AUTOSAR XML (schema 00048)
package /COM/VECTOR/CFG/WORKFLOW/SYSDESC/SYNC
  system SYSTEM: category=ECU_EXTRACT
    system mapping MAPPINGS
      data-mappings:
        sender-receiver-to-signal-mapping={communication-direction=OUT, data-element=COMPOSITIONTYPE.SP_IF_BMC_Abschaltankuendigung_XIX_BMC_HV.DE_BMC_Abschaltankuendigung, system-signal=BMC_Abschaltankuendigung}
        sender-receiver-to-signal-mapping={communication-direction=OUT, data-element=COMPOSITIONTYPE.SP_IF_BMC_Bidi_Energie_Absolut_XIX_BMC_HV.DE_BMC_Bidi_Energie_Absolut, system-signal=BMC_Bidi_Energie_Absolut}
        sender-receiver-to-signal-mapping={communication-direction=OUT, data-element=COMPOSITIONTYPE.SP_IF_BMC_Bidi_GenutzteEnergie_XIX_BMC_HV.DE_BMC_Bidi_GenutzteEnergie, system-signal=BMC_Bidi_GenutzteEnergie}
        sender-receiver-to-signal-mapping={communication-direction=OUT, data-element=COMPOSITIONTYPE.SP_IF_BMC_Bidi_Max_SoC_XIX_BMC_HV.DE_BMC_Bidi_Max_SoC, system-signal=BMC_Bidi_Max_SoC}
        sender-receiver-to-signal-mapping={communication-direction=OUT, data-element=COMPOSITIONTYPE.SP_IF_BMC_Bidi_Min_SoC_XIX_BMC_HV.DE_BMC_Bidi_Min_SoC, system-signal=BMC_Bidi_Min_SoC}
        sender-receiver-to-signal-mapping={communication-direction=OUT, data-element=COMPOSITIONTYPE.SP_IF_BMC_CMC_Temperatur_{001..019}_XIX_BMC_HV.DE_BMC_CMC_Temperatur_{001..019}, system-signal=BMC_CMC_Temperatur_{001..019}}
        sender-receiver-to-signal-mapping={communication-direction=OUT, data-element=COMPOSITIONTYPE.SP_IF_BMC_CMC_Temperatur_01_Messzeit_XIX_BMC_HV.DE_BMC_CMC_Temperatur_01_Messzeit, system-signal=BMC_CMC_Temperatur_01_Messzeit}
        sender-receiver-to-signal-mapping={communication-direction=OUT, data-element=COMPOSITIONTYPE.SP_IF_BMC_CMC_Temperatur_{020..029}_XIX_BMC_HV.DE_BMC_CMC_Temperatur_{020..029}, system-signal=BMC_CMC_Temperatur_{020..029}}
        sender-receiver-to-signal-mapping={communication-direction=OUT, data-element=COMPOSITIONTYPE.SP_IF_BMC_CMC_Temperatur_02_Messzeit_XIX_BMC_HV.DE_BMC_CMC_Temperatur_02_Messzeit, system-signal=BMC_CMC_Temperatur_02_Messzeit}
        sender-receiver-to-signal-mapping={communication-direction=OUT, data-element=COMPOSITIONTYPE.SP_IF_BMC_CMC_Temperatur_{030..039}_XIX_BMC_HV.DE_BMC_CMC_Temperatur_{030..039}, system-signal=BMC_CMC_Temperatur_{030..039}}
        sender-receiver-to-signal-mapping={communication-direction=OUT, data-element=COMPOSITIONTYPE.SP_IF_BMC_CMC_Temperatur_03_Messzeit_XIX_BMC_HV.DE_BMC_CMC_Temperatur_03_Messzeit, system-signal=BMC_CMC_Temperatur_03_Messzeit}
        sender-receiver-to-signal-mapping={communication-direction=OUT, data-element=COMPOSITIONTYPE.SP_IF_BMC_CMC_Temperatur_{040..096}_XIX_BMC_HV.DE_BMC_CMC_Temperatur_{040..096}, system-signal=BMC_CMC_Temperatur_{040..096}}
        sender-receiver-to-signal-mapping={communication-direction=OUT, data-element=COMPOSITIONTYPE.SP_IF_BMC_CMC_Zellspannung_{001..019}_XIX_BMC_HV.DE_BMC_CMC_Zellspannung_{001..019}, system-signal=BMC_CMC_Zellspannung_{001..019}}
        sender-receiver-to-signal-mapping={communication-direction=OUT, data-element=COMPOSITIONTYPE.SP_IF_BMC_CMC_Zellspannung_01_Messzeit_XIX_BMC_HV.DE_BMC_CMC_Zellspannung_01_Messzeit, system-signal=BMC_CMC_Zellspannung_01_Messzeit}
        sender-receiver-to-signal-mapping={communication-direction=OUT, data-element=COMPOSITIONTYPE.SP_IF_BMC_CMC_Zellspannung_{020..029}_XIX_BMC_HV.DE_BMC_CMC_Zellspannung_{020..029}, system-signal=BMC_CMC_Zellspannung_{020..029}}
        sender-receiver-to-signal-mapping={communication-direction=OUT, data-element=COMPOSITIONTYPE.SP_IF_BMC_CMC_Zellspannung_02_Messzeit_XIX_BMC_HV.DE_BMC_CMC_Zellspannung_02_Messzeit, system-signal=BMC_CMC_Zellspannung_02_Messzeit}
        sender-receiver-to-signal-mapping={communication-direction=OUT, data-element=COMPOSITIONTYPE.SP_IF_BMC_CMC_Zellspannung_{030..039}_XIX_BMC_HV.DE_BMC_CMC_Zellspannung_{030..039}, system-signal=BMC_CMC_Zellspannung_{030..039}}
        sender-receiver-to-signal-mapping={communication-direction=OUT, data-element=COMPOSITIONTYPE.SP_IF_BMC_CMC_Zellspannung_03_Messzeit_XIX_BMC_HV.DE_BMC_CMC_Zellspannung_03_Messzeit, system-signal=BMC_CMC_Zellspannung_03_Messzeit}
        sender-receiver-to-signal-mapping={communication-direction=OUT, data-element=COMPOSITIONTYPE.SP_IF_BMC_CMC_Zellspannung_{040..049}_XIX_BMC_HV.DE_BMC_CMC_Zellspannung_{040..049}, system-signal=BMC_CMC_Zellspannung_{040..049}}
        sender-receiver-to-signal-mapping={communication-direction=OUT, data-element=COMPOSITIONTYPE.SP_IF_BMC_CMC_Zellspannung_04_Messzeit_XIX_BMC_HV.DE_BMC_CMC_Zellspannung_04_Messzeit, system-signal=BMC_CMC_Zellspannung_04_Messzeit}
        sender-receiver-to-signal-mapping={communication-direction=OUT, data-element=COMPOSITIONTYPE.SP_IF_BMC_CMC_Zellspannung_{050..059}_XIX_BMC_HV.DE_BMC_CMC_Zellspannung_{050..059}, system-signal=BMC_CMC_Zellspannung_{050..059}}
        sender-receiver-to-signal-mapping={communication-direction=OUT, data-element=COMPOSITIONTYPE.SP_IF_BMC_CMC_Zellspannung_05_Messzeit_XIX_BMC_HV.DE_BMC_CMC_Zellspannung_05_Messzeit, system-signal=BMC_CMC_Zellspannung_05_Messzeit}
        sender-receiver-to-signal-mapping={communication-direction=OUT, data-element=COMPOSITIONTYPE.SP_IF_BMC_CMC_Zellspannung_{060..192}_XIX_BMC_HV.DE_BMC_CMC_Zellspannung_{060..192}, system-signal=BMC_CMC_Zellspannung_{060..192}}
        sender-receiver-to-signal-mapping={communication-direction=OUT, data-element=COMPOSITIONTYPE.SP_IF_BMC_Dauer_Entladeleistung_02_XIX_BMC_HV.DE_BMC_Dauer_Entladeleistung_02, system-signal=BMC_Dauer_Entladeleistung_02}
        sender-receiver-to-signal-mapping={communication-direction=OUT, data-element=COMPOSITIONTYPE.SP_IF_BMC_Dauer_Entladeleistung_XIX_BMC_HV.DE_BMC_Dauer_Entladeleistung, system-signal=BMC_Dauer_Entladeleistung}
        sender-receiver-to-signal-mapping={communication-direction=OUT, data-element=COMPOSITIONTYPE.SP_IF_BMC_Dauer_Ladeleistung_02_XIX_BMC_HV.DE_BMC_Dauer_Ladeleistung_02, system-signal=BMC_Dauer_Ladeleistung_02}
        sender-receiver-to-signal-mapping={communication-direction=OUT, data-element=COMPOSITIONTYPE.SP_IF_BMC_Dauer_Ladeleistung_XIX_BMC_HV.DE_BMC_Dauer_Ladeleistung, system-signal=BMC_Dauer_Ladeleistung}
        sender-receiver-to-signal-mapping={communication-direction=OUT, data-element=COMPOSITIONTYPE.SP_IF_BMC_Energie_Entladen_XIX_BMC_HV.DE_BMC_Energie_Entladen, system-signal=BMC_Energie_Entladen}
        sender-receiver-to-signal-mapping={communication-direction=OUT, data-element=COMPOSITIONTYPE.SP_IF_BMC_Energie_Laden_XIX_BMC_HV.DE_BMC_Energie_Laden, system-signal=BMC_Energie_Laden}
        sender-receiver-to-signal-mapping={communication-direction=OUT, data-element=COMPOSITIONTYPE.SP_IF_BMC_EnergieVorhalt_XIX_BMC_HV.DE_BMC_EnergieVorhalt, system-signal=BMC_EnergieVorhalt}
        sender-receiver-to-signal-mapping={communication-direction=OUT, data-element=COMPOSITIONTYPE.SP_IF_BMC_ExtLadeleistung_XIX_BMC_HV.DE_BMC_ExtLadeleistung, system-signal=BMC_ExtLadeleistung}
        sender-receiver-to-signal-mapping={communication-direction=OUT, data-element=COMPOSITIONTYPE.SP_IF_BMC_IstTemperaturMax_Modul_ID_XIX_BMC_HV.DE_BMC_IstTemperaturMax_Modul_ID, system-signal=BMC_IstTemperaturMax_Modul_ID}
        sender-receiver-to-signal-mapping={communication-direction=OUT, data-element=COMPOSITIONTYPE.SP_IF_BMC_IstTemperaturMax_Sensor_ID_XIX_BMC_HV.DE_BMC_IstTemperaturMax_Sensor_ID, system-signal=BMC_IstTemperaturMax_Sensor_ID}
        sender-receiver-to-signal-mapping={communication-direction=OUT, data-element=COMPOSITIONTYPE.SP_IF_BMC_IstTemperaturMin_Modul_ID_XIX_BMC_HV.DE_BMC_IstTemperaturMin_Modul_ID, system-signal=BMC_IstTemperaturMin_Modul_ID}
        sender-receiver-to-signal-mapping={communication-direction=OUT, data-element=COMPOSITIONTYPE.SP_IF_BMC_IstTemperaturMin_Sensor_ID_XIX_BMC_HV.DE_BMC_IstTemperaturMin_Sensor_ID, system-signal=BMC_IstTemperaturMin_Sensor_ID}
        sender-receiver-to-signal-mapping={communication-direction=OUT, data-element=COMPOSITIONTYPE.SP_IF_BMC_IstZellSpannungMax_Modul_ID_XIX_BMC_HV.DE_BMC_IstZellSpannungMax_Modul_ID, system-signal=BMC_IstZellSpannungMax_Modul_ID}
        sender-receiver-to-signal-mapping={communication-direction=OUT, data-element=COMPOSITIONTYPE.SP_IF_BMC_IstZellSpannungMax_Zell_ID_XIX_BMC_HV.DE_BMC_IstZellSpannungMax_Zell_ID, system-signal=BMC_IstZellSpannungMax_Zell_ID}
        sender-receiver-to-signal-mapping={communication-direction=OUT, data-element=COMPOSITIONTYPE.SP_IF_BMC_IstZellSpannungMin_Modul_ID_XIX_BMC_HV.DE_BMC_IstZellSpannungMin_Modul_ID, system-signal=BMC_IstZellSpannungMin_Modul_ID}
        sender-receiver-to-signal-mapping={communication-direction=OUT, data-element=COMPOSITIONTYPE.SP_IF_BMC_IstZellSpannungMin_Zell_ID_XIX_BMC_HV.DE_BMC_IstZellSpannungMin_Zell_ID, system-signal=BMC_IstZellSpannungMin_Zell_ID}
        sender-receiver-to-signal-mapping={communication-direction=OUT, data-element=COMPOSITIONTYPE.SP_IF_BMC_Max_Entladeleistung_02_XIX_BMC_HV.DE_BMC_Max_Entladeleistung_02, system-signal=BMC_Max_Entladeleistung_02}
        sender-receiver-to-signal-mapping={communication-direction=OUT, data-element=COMPOSITIONTYPE.SP_IF_BMC_Max_Entladestrom_02_XIX_BMC_HV.DE_BMC_Max_Entladestrom_02, system-signal=BMC_Max_Entladestrom_02}
        sender-receiver-to-signal-mapping={communication-direction=OUT, data-element=COMPOSITIONTYPE.SP_IF_BMC_Max_Ladeleistung_02_XIX_BMC_HV.DE_BMC_Max_Ladeleistung_02, system-signal=BMC_Max_Ladeleistung_02}
        sender-receiver-to-signal-mapping={communication-direction=OUT, data-element=COMPOSITIONTYPE.SP_IF_BMC_Max_Ladestrom_02_XIX_BMC_HV.DE_BMC_Max_Ladestrom_02, system-signal=BMC_Max_Ladestrom_02}
        sender-receiver-to-signal-mapping={communication-direction=OUT, data-element=COMPOSITIONTYPE.SP_IF_BMC_Max_Spannung_XIX_BMC_HV.DE_BMC_Max_Spannung, system-signal=BMC_Max_Spannung}
        sender-receiver-to-signal-mapping={communication-direction=OUT, data-element=COMPOSITIONTYPE.SP_IF_BMC_MaxEnergieinhalt_XIX_BMC_HV.DE_BMC_MaxEnergieinhalt, system-signal=BMC_MaxEnergieinhalt}
        sender-receiver-to-signal-mapping={communication-direction=OUT, data-element=COMPOSITIONTYPE.SP_IF_BMC_Min_Spannung_XIX_BMC_HV.DE_BMC_Min_Spannung, system-signal=BMC_Min_Spannung}
        sender-receiver-to-signal-mapping={communication-direction=OUT, data-element=COMPOSITIONTYPE.SP_IF_BMC_NutzbareKapazitaet_XIX_BMC_HV.DE_BMC_NutzbareKapazitaet, system-signal=BMC_NutzbareKapazitaet}
        sender-receiver-to-signal-mapping={communication-direction=OUT, data-element=COMPOSITIONTYPE.SP_IF_BMC_Range_Indikator_XIX_BMC_HV.DE_BMC_Range_Indikator, system-signal=BMC_Range_Indikator}
        sender-receiver-to-signal-mapping={communication-direction=OUT, data-element=COMPOSITIONTYPE.SP_IF_BMC_Rekuperation_XIX_BMC_HV.DE_BMC_Rekuperation, system-signal=BMC_Rekuperation}
        sender-receiver-to-signal-mapping={communication-direction=OUT, data-element=COMPOSITIONTYPE.SP_IF_BMC_RuecklaufTemperatur_XIX_BMC_HV.DE_BMC_RuecklaufTemperatur, system-signal=BMC_RuecklaufTemperatur}
        sender-receiver-to-signal-mapping={communication-direction=OUT, data-element=COMPOSITIONTYPE.SP_IF_BMC_Temperatur_hoechste_XIX_BMC_HV.DE_BMC_Temperatur_hoechste, system-signal=BMC_Temperatur_hoechste}
        sender-receiver-to-signal-mapping={communication-direction=OUT, data-element=COMPOSITIONTYPE.SP_IF_BMC_Temperatur_niedrigste_XIX_BMC_HV.DE_BMC_Temperatur_niedrigste, system-signal=BMC_Temperatur_niedrigste}
        sender-receiver-to-signal-mapping={communication-direction=OUT, data-element=COMPOSITIONTYPE.SP_IF_BMC_Temperatur_XIX_BMC_HV.DE_BMC_Temperatur, system-signal=BMC_Temperatur}
        sender-receiver-to-signal-mapping={communication-direction=OUT, data-element=COMPOSITIONTYPE.SP_IF_BMC_ThermAuslastung_XIX_BMC_HV.DE_BMC_ThermAuslastung, system-signal=BMC_ThermAuslastung}
        sender-receiver-to-signal-mapping={communication-direction=OUT, data-element=COMPOSITIONTYPE.SP_IF_BMC_ThermSpreizung_XIX_BMC_HV.DE_BMC_ThermSpreizung, system-signal=BMC_ThermSpreizung}
        sender-receiver-to-signal-mapping={communication-direction=OUT, data-element=COMPOSITIONTYPE.SP_IF_BMC_UBE_Indik_last_update_km_XIX_BMC_HV.DE_BMC_UBE_Indik_last_update_km, system-signal=BMC_UBE_Indik_last_update_km}
        sender-receiver-to-signal-mapping={communication-direction=OUT, data-element=COMPOSITIONTYPE.SP_IF_BMC_UBE_Indikator_XIX_BMC_HV.DE_BMC_UBE_Indikator, system-signal=BMC_UBE_Indikator}
        sender-receiver-to-signal-mapping={communication-direction=OUT, data-element=COMPOSITIONTYPE.SP_IF_BMC_Verbrauch_XIX_BMC_HV.DE_BMC_Verbrauch, system-signal=BMC_Verbrauch}
        sender-receiver-to-signal-mapping={communication-direction=OUT, data-element=COMPOSITIONTYPE.SP_IF_BMC_VerlustEnergie_XIX_BMC_HV.DE_BMC_VerlustEnergie, system-signal=BMC_VerlustEnergie}
        sender-receiver-to-signal-mapping={communication-direction=OUT, data-element=COMPOSITIONTYPE.SP_IF_BMC_VorlaufTemperatur_XIX_BMC_HV.DE_BMC_VorlaufTemperatur, system-signal=BMC_VorlaufTemperatur}
        sender-receiver-to-signal-mapping={communication-direction=OUT, data-element=COMPOSITIONTYPE.SP_IF_DS_Hybrid_01_ConfDTCChanged_XIX_BMC_HV.DE_DS_Hybrid_01_ConfDTCChanged, system-signal=DS_Hybrid_01_ConfDTCChanged}
        sender-receiver-to-signal-mapping={communication-direction=OUT, data-element=COMPOSITIONTYPE.SP_IF_DS_Hybrid_01_DiagAdr_XIX_BMC_HV.DE_DS_Hybrid_01_DiagAdr, system-signal=DS_Hybrid_01_DiagAdr}
        sender-receiver-to-signal-mapping={communication-direction=OUT, data-element=COMPOSITIONTYPE.SP_IF_DS_Hybrid_01_MemSel10Changed_XIX_BMC_HV.DE_DS_Hybrid_01_MemSel10Changed, system-signal=DS_Hybrid_01_MemSel10Changed}
        sender-receiver-to-signal-mapping={communication-direction=OUT, data-element=COMPOSITIONTYPE.SP_IF_DS_Hybrid_01_MemSelChanged_XIX_BMC_HV.DE_DS_Hybrid_01_MemSelChanged, system-signal=DS_Hybrid_01_MemSelChanged}
        sender-receiver-to-signal-mapping={communication-direction=OUT, data-element=COMPOSITIONTYPE.SP_IF_DS_Hybrid_01_StMemChanged_XIX_BMC_HV.DE_DS_Hybrid_01_StMemChanged, system-signal=DS_Hybrid_01_StMemChanged}
        sender-receiver-to-signal-mapping={communication-direction=OUT, data-element=COMPOSITIONTYPE.SP_IF_DS_Hybrid_01_TestFailedChanged_XIX_BMC_HV.DE_DS_Hybrid_01_TestFailedChanged, system-signal=DS_Hybrid_01_TestFailedChanged}
        sender-receiver-to-signal-mapping={communication-direction=OUT, data-element=COMPOSITIONTYPE.SP_IF_DS_Hybrid_01_WIRChanged_XIX_BMC_HV.DE_DS_Hybrid_01_WIRChanged, system-signal=DS_Hybrid_01_WIRChanged}
        sender-receiver-to-signal-mapping={communication-direction=OUT, data-element=COMPOSITIONTYPE.SP_IF_Hybrid_01_SNI_10_XIX_BMC_HV.DE_Hybrid_01_SNI_10, system-signal=Hybrid_01_SNI_10}
        sender-receiver-to-signal-mapping={communication-direction=OUT, data-element=COMPOSITIONTYPE.SP_IF_SOK_Zeit_Hybrid_01_Challenge_XIX_BMC_HV.DE_SOK_Zeit_Hybrid_01_Challenge, system-signal=SOK_Zeit_Hybrid_01_Challenge}
        sender-receiver-to-signal-mapping={communication-direction=IN, data-element=COMPOSITIONTYPE.RP_IF_BJB_CALID_Index_{01..16}_XIX_BMC_HV.DE_BJB_CALID_Index_{01..16}, system-signal=BJB_CALID_Index_{01..16}}
        sender-receiver-to-signal-mapping={communication-direction=IN, data-element=COMPOSITIONTYPE.RP_IF_BJB_CVN_Byte_{1..4}_XIX_BMC_HV.DE_BJB_CVN_Byte_{1..4}, system-signal=BJB_CVN_Byte_{1..4}}
        sender-receiver-to-signal-mapping={communication-direction=IN, data-element=COMPOSITIONTYPE.RP_IF_BJB_CVN_VLD_XIX_BMC_HV.DE_BJB_CVN_VLD, system-signal=BJB_CVN_VLD}
        sender-receiver-to-signal-mapping={communication-direction=IN, data-element=COMPOSITIONTYPE.RP_IF_CHA_ReqPrgBms_XIX_BMC_HV.DE_CHA_ReqPrgBms, system-signal=CHA_ReqPrgBms}
        sender-receiver-to-signal-mapping={communication-direction=IN, data-element=COMPOSITIONTYPE.RP_IF_DC_IstLeistung_HV_XIX_BMC_HV.DE_DC_IstLeistung_HV, system-signal=DC_IstLeistung_HV}
        sender-receiver-to-signal-mapping={communication-direction=IN, data-element=COMPOSITIONTYPE.RP_IF_DCDC_NV_CALID_Index_{01..16}_XIX_BMC_HV.DE_DCDC_NV_CALID_Index_{01..16}, system-signal=DCDC_NV_CALID_Index_{01..16}}
        sender-receiver-to-signal-mapping={communication-direction=IN, data-element=COMPOSITIONTYPE.RP_IF_DCDC_NV_CVN_Byte_{1..4}_XIX_BMC_HV.DE_DCDC_NV_CVN_Byte_{1..4}, system-signal=DCDC_NV_CVN_Byte_{1..4}}
        sender-receiver-to-signal-mapping={communication-direction=IN, data-element=COMPOSITIONTYPE.RP_IF_DCDC_NV_CVN_VLD_XIX_BMC_HV.DE_DCDC_NV_CVN_VLD, system-signal=DCDC_NV_CVN_VLD}
        sender-receiver-to-signal-mapping={communication-direction=IN, data-element=COMPOSITIONTYPE.RP_IF_DCDC_NV_Komponentenfehler_{01..39}_XIX_BMC_HV.DE_DCDC_NV_Komponentenfehler_{01..39}, system-signal=DCDC_NV_Komponentenfehler_{01..39}}
        sender-receiver-to-signal-mapping={communication-direction=IN, data-element=COMPOSITIONTYPE.RP_IF_DCDC_NV_Komponentenfehler_3_{10..16}_XIX_BMC_HV.DE_DCDC_NV_Komponentenfehler_3_{10..16}, system-signal=DCDC_NV_Komponentenfehler_3_{10..16}}
        sender-receiver-to-signal-mapping={communication-direction=IN, data-element=COMPOSITIONTYPE.RP_IF_DCDC_NV_Komponentenfehler_3_{1..9}_XIX_BMC_HV.DE_DCDC_NV_Komponentenfehler_3_{1..9}, system-signal=DCDC_NV_Komponentenfehler_3_{1..9}}
        sender-receiver-to-signal-mapping={communication-direction=IN, data-element=COMPOSITIONTYPE.RP_IF_DCDC_NV_Komponentenfehler_{40..80}_XIX_BMC_HV.DE_DCDC_NV_Komponentenfehler_{40..80}, system-signal=DCDC_NV_Komponentenfehler_{40..80}}
        sender-receiver-to-signal-mapping={communication-direction=IN, data-element=COMPOSITIONTYPE.RP_IF_DCDC_NV_Komponentenfehler_VLD_XIX_BMC_HV.DE_DCDC_NV_Komponentenfehler_VLD, system-signal=DCDC_NV_Komponentenfehler_VLD}
        sender-receiver-to-signal-mapping={communication-direction=IN, data-element=COMPOSITIONTYPE.RP_IF_DW_Kilometerstand_XIX_BMC_HV.DE_DW_Kilometerstand, system-signal=DW_Kilometerstand}
        sender-receiver-to-signal-mapping={communication-direction=IN, data-element=COMPOSITIONTYPE.RP_IF_EKK_HVK_EoHVL_Status_XIX_BMC_HV.DE_EKK_HVK_EoHVL_Status, system-signal=EKK_HVK_EoHVL_Status}
        sender-receiver-to-signal-mapping={communication-direction=IN, data-element=COMPOSITIONTYPE.RP_IF_HVEM_BMC_CHA_Wunschleistung_02_XIX_BMC_HV.DE_HVEM_BMC_CHA_Wunschleistung_02, system-signal=HVEM_BMC_CHA_Wunschleistung_02}
        sender-receiver-to-signal-mapping={communication-direction=IN, data-element=COMPOSITIONTYPE.RP_IF_HVEM_BMC_CHA_Wunschleistung_XIX_BMC_HV.DE_HVEM_BMC_CHA_Wunschleistung, system-signal=HVEM_BMC_CHA_Wunschleistung}
        sender-receiver-to-signal-mapping={communication-direction=IN, data-element=COMPOSITIONTYPE.RP_IF_HVEM_MMTR_State_XIX_BMC_HV.DE_HVEM_MMTR_State, system-signal=HVEM_MMTR_State}
        sender-receiver-to-signal-mapping={communication-direction=IN, data-element=COMPOSITIONTYPE.RP_IF_HVEM_SystemMinLeistungsgrenze_XIX_BMC_HV.DE_HVEM_SystemMinLeistungsgrenze, system-signal=HVEM_SystemMinLeistungsgrenze}
        sender-receiver-to-signal-mapping={communication-direction=IN, data-element=COMPOSITIONTYPE.RP_IF_HVLE_IstSpannung_HV_XIX_BMC_HV.DE_HVLE_IstSpannung_HV, system-signal=HVLE_IstSpannung_HV}
        sender-receiver-to-signal-mapping={communication-direction=IN, data-element=COMPOSITIONTYPE.RP_IF_HVLE_OBG_IstModus_XIX_BMC_HV.DE_HVLE_OBG_IstModus, system-signal=HVLE_OBG_IstModus}
        sender-receiver-to-signal-mapping={communication-direction=IN, data-element=COMPOSITIONTYPE.RP_IF_HVLM_BCAM_Aktiv_XIX_BMC_HV.DE_HVLM_BCAM_Aktiv, system-signal=HVLM_BCAM_Aktiv}
        sender-receiver-to-signal-mapping={communication-direction=IN, data-element=COMPOSITIONTYPE.RP_IF_HVLM_BidiLadeModus_XIX_BMC_HV.DE_HVLM_BidiLadeModus, system-signal=HVLM_BidiLadeModus}
        sender-receiver-to-signal-mapping={communication-direction=IN, data-element=COMPOSITIONTYPE.RP_IF_KST_KL_15_XIX_BMC_HV.DE_KST_KL_15, system-signal=KST_KL_15}
        sender-receiver-to-signal-mapping={communication-direction=IN, data-element=COMPOSITIONTYPE.RP_IF_MM_PropulsionSystemActive_XIX_BMC_HV.DE_MM_PropulsionSystemActive, system-signal=MM_PropulsionSystemActive}
        sender-receiver-to-signal-mapping={communication-direction=IN, data-element=COMPOSITIONTYPE.RP_IF_NVEM_Abschaltstufe_XIX_BMC_HV.DE_NVEM_Abschaltstufe, system-signal=NVEM_Abschaltstufe}
        sender-receiver-to-signal-mapping={communication-direction=IN, data-element=COMPOSITIONTYPE.RP_IF_OBD_Abs_Pedal_Pos_XIX_BMC_HV.DE_OBD_Abs_Pedal_Pos, system-signal=OBD_Abs_Pedal_Pos}
        sender-receiver-to-signal-mapping={communication-direction=IN, data-element=COMPOSITIONTYPE.RP_IF_OBD_Aussen_Temp_gef_XIX_BMC_HV.DE_OBD_Aussen_Temp_gef, system-signal=OBD_Aussen_Temp_gef}
        sender-receiver-to-signal-mapping={communication-direction=IN, data-element=COMPOSITIONTYPE.RP_IF_OBD_Barometric_Pressure_XIX_BMC_HV.DE_OBD_Barometric_Pressure, system-signal=OBD_Barometric_Pressure}
        sender-receiver-to-signal-mapping={communication-direction=IN, data-element=COMPOSITIONTYPE.RP_IF_OBD_Calc_Load_Val_XIX_BMC_HV.DE_OBD_Calc_Load_Val, system-signal=OBD_Calc_Load_Val}
        sender-receiver-to-signal-mapping={communication-direction=IN, data-element=COMPOSITIONTYPE.RP_IF_OBD_ClearMem_Inhibit_XIX_BMC_HV.DE_OBD_ClearMem_Inhibit, system-signal=OBD_ClearMem_Inhibit}
        sender-receiver-to-signal-mapping={communication-direction=IN, data-element=COMPOSITIONTYPE.RP_IF_OBD_Driving_Cycle_XIX_BMC_HV.DE_OBD_Driving_Cycle, system-signal=OBD_Driving_Cycle}
        sender-receiver-to-signal-mapping={communication-direction=IN, data-element=COMPOSITIONTYPE.RP_IF_OBD_Eng_Cool_Temp_XIX_BMC_HV.DE_OBD_Eng_Cool_Temp, system-signal=OBD_Eng_Cool_Temp}
        sender-receiver-to-signal-mapping={communication-direction=IN, data-element=COMPOSITIONTYPE.RP_IF_OBD_Engine_RPM_XIX_BMC_HV.DE_OBD_Engine_RPM, system-signal=OBD_Engine_RPM}
        sender-receiver-to-signal-mapping={communication-direction=IN, data-element=COMPOSITIONTYPE.RP_IF_OBD_Kaltstart_Denominator_XIX_BMC_HV.DE_OBD_Kaltstart_Denominator, system-signal=OBD_Kaltstart_Denominator}
        sender-receiver-to-signal-mapping={communication-direction=IN, data-element=COMPOSITIONTYPE.RP_IF_OBD_Minimum_Trip_XIX_BMC_HV.DE_OBD_Minimum_Trip, system-signal=OBD_Minimum_Trip}
        sender-receiver-to-signal-mapping={communication-direction=IN, data-element=COMPOSITIONTYPE.RP_IF_OBD_Normed_Trip_XIX_BMC_HV.DE_OBD_Normed_Trip, system-signal=OBD_Normed_Trip}
        sender-receiver-to-signal-mapping={communication-direction=IN, data-element=COMPOSITIONTYPE.RP_IF_OBD_NumDcyMilOnReq_XIX_BMC_HV.DE_OBD_NumDcyMilOnReq, system-signal=OBD_NumDcyMilOnReq}
        sender-receiver-to-signal-mapping={communication-direction=IN, data-element=COMPOSITIONTYPE.RP_IF_OBD_QBit_Aussen_Temp_XIX_BMC_HV.DE_OBD_QBit_Aussen_Temp, system-signal=OBD_QBit_Aussen_Temp}
        sender-receiver-to-signal-mapping={communication-direction=IN, data-element=COMPOSITIONTYPE.RP_IF_OBD_Sperrung_IUMPR_XIX_BMC_HV.DE_OBD_Sperrung_IUMPR, system-signal=OBD_Sperrung_IUMPR}
        sender-receiver-to-signal-mapping={communication-direction=IN, data-element=COMPOSITIONTYPE.RP_IF_OBD_Sperrung_Kaltstart_Denom_XIX_BMC_HV.DE_OBD_Sperrung_Kaltstart_Denom, system-signal=OBD_Sperrung_Kaltstart_Denom}
        sender-receiver-to-signal-mapping={communication-direction=IN, data-element=COMPOSITIONTYPE.RP_IF_OBD_Typ_XIX_BMC_HV.DE_OBD_Typ, system-signal=OBD_Typ}
        sender-receiver-to-signal-mapping={communication-direction=IN, data-element=COMPOSITIONTYPE.RP_IF_OBD_Warm_Up_Cycle_XIX_BMC_HV.DE_OBD_Warm_Up_Cycle, system-signal=OBD_Warm_Up_Cycle}
        sender-receiver-to-signal-mapping={communication-direction=IN, data-element=COMPOSITIONTYPE.RP_IF_OBDProtocol_req_XIX_BMC_HV.DE_OBDProtocol_req, system-signal=OBDProtocol_req}
        sender-receiver-to-signal-mapping={communication-direction=IN, data-element=COMPOSITIONTYPE.RP_IF_ORU_Status_XIX_BMC_HV.DE_ORU_Status, system-signal=ORU_Status}
        sender-receiver-to-signal-mapping={communication-direction=IN, data-element=COMPOSITIONTYPE.RP_IF_OTP_Aussen_Temp_OBD_XIX_BMC_HV.DE_OTP_Aussen_Temp_OBD, system-signal=OTP_Aussen_Temp_OBD}
        sender-receiver-to-signal-mapping={communication-direction=IN, data-element=COMPOSITIONTYPE.RP_IF_OTP_Aussen_Temp_ungef_XIX_BMC_HV.DE_OTP_Aussen_Temp_ungef, system-signal=OTP_Aussen_Temp_ungef}
        sender-receiver-to-signal-mapping={communication-direction=IN, data-element=COMPOSITIONTYPE.RP_IF_PCM_BMC_VTD_Freeze_Req_XIX_BMC_HV.DE_PCM_BMC_VTD_Freeze_Req, system-signal=PCM_BMC_VTD_Freeze_Req}
        sender-receiver-to-signal-mapping={communication-direction=IN, data-element=COMPOSITIONTYPE.RP_IF_PCM_BMC_VTD_LifeTimeReset_Req_XIX_BMC_HV.DE_PCM_BMC_VTD_LifeTimeReset_Req, system-signal=PCM_BMC_VTD_LifeTimeReset_Req}
        sender-receiver-to-signal-mapping={communication-direction=IN, data-element=COMPOSITIONTYPE.RP_IF_PCM_BMC_VTD_LifeTimeReset_Resp_XIX_BMC_HV.DE_PCM_BMC_VTD_LifeTimeReset_Resp, system-signal=PCM_BMC_VTD_LifeTimeReset_Resp}
        sender-receiver-to-signal-mapping={communication-direction=IN, data-element=COMPOSITIONTYPE.RP_IF_PCM_BMC_VTD_RecentReset_Req_XIX_BMC_HV.DE_PCM_BMC_VTD_RecentReset_Req, system-signal=PCM_BMC_VTD_RecentReset_Req}
        sender-receiver-to-signal-group-mapping={communication-direction=IN, data-element=COMPOSITIONTYPE.RP_IF_SG_KS_Hybrid_01_Challenge_M_XIX_BMC_HV.DE_SG_KS_Hybrid_01_Challenge_M, signal-group=SG_KS_Hybrid_01_Challenge_M, type-mapping=sender-rec-record-type-mapping=record-element-mappings=[{implementation-record-element=KS_Hybrid_01_ChM_SID, system-signal=KS_Hybrid_01_ChM_SID}, {implementation-record-element=KS_Hybrid_01_ChM_IKACtr, system-signal=KS_Hybrid_01_ChM_IKACtr}, {implementation-record-element=KS_Hybrid_01_ChM, system-signal=KS_Hybrid_01_ChM}]}
        sender-receiver-to-signal-group-mapping={communication-direction=IN, data-element=COMPOSITIONTYPE.RP_IF_SG_KS_Hybrid_01_Response_M_XIX_BMC_HV.DE_SG_KS_Hybrid_01_Response_M, signal-group=SG_KS_Hybrid_01_Response_M, type-mapping=sender-rec-record-type-mapping=record-element-mappings=[{implementation-record-element=KS_Hybrid_01_ReM_SID, system-signal=KS_Hybrid_01_ReM_SID}, {implementation-record-element=KS_Hybrid_01_ReM_IKACtr, system-signal=KS_Hybrid_01_ReM_IKACtr}, {implementation-record-element=KS_Hybrid_01_ReM, system-signal=KS_Hybrid_01_ReM}]}
        sender-receiver-to-signal-mapping={communication-direction=IN, data-element=COMPOSITIONTYPE.RP_IF_SI_NWDF_30_XIX_BMC_HV.DE_SI_NWDF_30, system-signal=SI_NWDF_30}
        sender-receiver-to-signal-mapping={communication-direction=IN, data-element=COMPOSITIONTYPE.RP_IF_SI_NWDF_XIX_BMC_HV.DE_SI_NWDF, system-signal=SI_NWDF}
        sender-receiver-to-signal-mapping={communication-direction=IN, data-element=COMPOSITIONTYPE.RP_IF_SI_P_Mode_gueltig_XIX_BMC_HV.DE_SI_P_Mode_gueltig, system-signal=SI_P_Mode_gueltig}
        sender-receiver-to-signal-mapping={communication-direction=IN, data-element=COMPOSITIONTYPE.RP_IF_SI_P_Mode_XIX_BMC_HV.DE_SI_P_Mode, system-signal=SI_P_Mode}
        sender-receiver-to-signal-mapping={communication-direction=IN, data-element=COMPOSITIONTYPE.RP_IF_SI_T_Mode_XIX_BMC_HV.DE_SI_T_Mode, system-signal=SI_T_Mode}
        sender-receiver-to-signal-mapping={communication-direction=IN, data-element=COMPOSITIONTYPE.RP_IF_SOK_ungeschuetzte_Zeit_XIX_BMC_HV.DE_SOK_ungeschuetzte_Zeit, system-signal=SOK_ungeschuetzte_Zeit}
        sender-receiver-to-signal-mapping={communication-direction=IN, data-element=COMPOSITIONTYPE.RP_IF_SOK_Zeit_Hybrid_01_Zeit_XIX_BMC_HV.DE_SOK_Zeit_Hybrid_01_Zeit, system-signal=SOK_Zeit_Hybrid_01_Zeit}
        sender-receiver-to-signal-mapping={communication-direction=IN, data-element=COMPOSITIONTYPE.RP_IF_TME_Batt_Kond_Verf_XIX_BMC_HV.DE_TME_Batt_Kond_Verf, system-signal=TME_Batt_Kond_Verf}
        sender-receiver-to-signal-mapping={communication-direction=IN, data-element=COMPOSITIONTYPE.RP_IF_TME_Therm_IstLeistung_HVBatterie_XIX_BMC_HV.DE_TME_Therm_IstLeistung_HVBatterie, system-signal=TME_Therm_IstLeistung_HVBatterie}
        sender-receiver-to-signal-mapping={communication-direction=IN, data-element=COMPOSITIONTYPE.RP_IF_UH_Jahr_XIX_BMC_HV.DE_UH_Jahr, system-signal=UH_Jahr}
        sender-receiver-to-signal-mapping={communication-direction=IN, data-element=COMPOSITIONTYPE.RP_IF_UH_Minute_XIX_BMC_HV.DE_UH_Minute, system-signal=UH_Minute}
        sender-receiver-to-signal-mapping={communication-direction=IN, data-element=COMPOSITIONTYPE.RP_IF_UH_Monat_XIX_BMC_HV.DE_UH_Monat, system-signal=UH_Monat}
        sender-receiver-to-signal-mapping={communication-direction=IN, data-element=COMPOSITIONTYPE.RP_IF_UH_Sekunde_XIX_BMC_HV.DE_UH_Sekunde, system-signal=UH_Sekunde}
        sender-receiver-to-signal-mapping={communication-direction=IN, data-element=COMPOSITIONTYPE.RP_IF_UH_Stunde_XIX_BMC_HV.DE_UH_Stunde, system-signal=UH_Stunde}
        sender-receiver-to-signal-mapping={communication-direction=IN, data-element=COMPOSITIONTYPE.RP_IF_UH_Tag_XIX_BMC_HV.DE_UH_Tag, system-signal=UH_Tag}
        sender-receiver-to-signal-mapping={communication-direction=IN, data-element=COMPOSITIONTYPE.RP_IF_UI1_Iso_Neg_XIX_BMC_HV.DE_UI1_Iso_Neg, system-signal=UI1_Iso_Neg}
        sender-receiver-to-signal-mapping={communication-direction=IN, data-element=COMPOSITIONTYPE.RP_IF_UI1_Iso_Pos_XIX_BMC_HV.DE_UI1_Iso_Pos, system-signal=UI1_Iso_Pos}
        sender-receiver-to-signal-mapping={communication-direction=IN, data-element=COMPOSITIONTYPE.RP_IF_UI1_Iso_Status_XIX_BMC_HV.DE_UI1_Iso_Status, system-signal=UI1_Iso_Status}
        sender-receiver-to-signal-mapping={communication-direction=IN, data-element=COMPOSITIONTYPE.RP_IF_UI1_KompFehlerModus2_{01..26}_XIX_BMC_HV.DE_UI1_KompFehlerModus2_{01..26}, system-signal=UI1_KompFehlerModus2_{01..26}}
        sender-receiver-to-signal-mapping={communication-direction=IN, data-element=COMPOSITIONTYPE.RP_IF_UI1_KompFehlerModus4_{01..16}_XIX_BMC_HV.DE_UI1_KompFehlerModus4_{01..16}, system-signal=UI1_KompFehlerModus4_{01..16}}
        sender-receiver-to-signal-mapping={communication-direction=IN, data-element=COMPOSITIONTYPE.RP_IF_UI1_Spannung{4..6}_XIX_BMC_HV.DE_UI1_Spannung{4..6}, system-signal=UI1_Spannung{4..6}}
        sender-receiver-to-signal-mapping={communication-direction=IN, data-element=COMPOSITIONTYPE.RP_IF_UI1_Status_XIX_BMC_HV.DE_UI1_Status, system-signal=UI1_Status}
        sender-receiver-to-signal-mapping={communication-direction=IN, data-element=COMPOSITIONTYPE.RP_IF_UI1_Stromintegral_Entladen_XIX_BMC_HV.DE_UI1_Stromintegral_Entladen, system-signal=UI1_Stromintegral_Entladen}
        sender-receiver-to-signal-mapping={communication-direction=IN, data-element=COMPOSITIONTYPE.RP_IF_UI1_Stromintegral_Laden_XIX_BMC_HV.DE_UI1_Stromintegral_Laden, system-signal=UI1_Stromintegral_Laden}
        sender-receiver-to-signal-mapping={communication-direction=IN, data-element=COMPOSITIONTYPE.RP_IF_UI1_Temperatur_1_XIX_BMC_HV.DE_UI1_Temperatur_1, system-signal=UI1_Temperatur_1}
        sender-receiver-to-signal-mapping={communication-direction=IN, data-element=COMPOSITIONTYPE.RP_IF_UI1_Temperatur_2_XIX_BMC_HV.DE_UI1_Temperatur_2, system-signal=UI1_Temperatur_2}
        sender-receiver-to-signal-mapping={communication-direction=IN, data-element=COMPOSITIONTYPE.RP_IF_UI2_KompFehlerModus2_{01..26}_XIX_BMC_HV.DE_UI2_KompFehlerModus2_{01..26}, system-signal=UI2_KompFehlerModus2_{01..26}}
        sender-receiver-to-signal-mapping={communication-direction=IN, data-element=COMPOSITIONTYPE.RP_IF_UI2_KompFehlerModus4_{01..16}_XIX_BMC_HV.DE_UI2_KompFehlerModus4_{01..16}, system-signal=UI2_KompFehlerModus4_{01..16}}
        sender-receiver-to-signal-mapping={communication-direction=IN, data-element=COMPOSITIONTYPE.RP_IF_UI2_Status_XIX_BMC_HV.DE_UI2_Status, system-signal=UI2_Status}
        sender-receiver-to-signal-mapping={communication-direction=IN, data-element=COMPOSITIONTYPE.RP_IF_UI2_Stromintegral_Entladen_XIX_BMC_HV.DE_UI2_Stromintegral_Entladen, system-signal=UI2_Stromintegral_Entladen}
        sender-receiver-to-signal-mapping={communication-direction=IN, data-element=COMPOSITIONTYPE.RP_IF_UI2_Stromintegral_Laden_XIX_BMC_HV.DE_UI2_Stromintegral_Laden, system-signal=UI2_Stromintegral_Laden}
        sender-receiver-to-signal-mapping={communication-direction=IN, data-element=COMPOSITIONTYPE.RP_IF_UI2_Temperatur_1_XIX_BMC_HV.DE_UI2_Temperatur_1, system-signal=UI2_Temperatur_1}
        sender-receiver-to-signal-mapping={communication-direction=IN, data-element=COMPOSITIONTYPE.RP_IF_UI2_Temperatur_2_XIX_BMC_HV.DE_UI2_Temperatur_2, system-signal=UI2_Temperatur_2}
        sender-receiver-to-signal-mapping={communication-direction=IN, data-element=COMPOSITIONTYPE.RP_IF_UI2Sens01_CALID_Index_{01..16}_XIX_BMC_HV.DE_UI2Sens01_CALID_Index_{01..16}, system-signal=UI2Sens01_CALID_Index_{01..16}}
        sender-receiver-to-signal-mapping={communication-direction=IN, data-element=COMPOSITIONTYPE.RP_IF_UI2Sens01_CVN_Byte_{1..4}_XIX_BMC_HV.DE_UI2Sens01_CVN_Byte_{1..4}, system-signal=UI2Sens01_CVN_Byte_{1..4}}
        sender-receiver-to-signal-mapping={communication-direction=IN, data-element=COMPOSITIONTYPE.RP_IF_UI2Sens01_CVN_VLD_XIX_BMC_HV.DE_UI2Sens01_CVN_VLD, system-signal=UI2Sens01_CVN_VLD}
        sender-receiver-to-signal-mapping={communication-direction=IN, data-element=COMPOSITIONTYPE.RP_IF_UI2Sens01_ErrMem_State_XIX_BMC_HV.DE_UI2Sens01_ErrMem_State, system-signal=UI2Sens01_ErrMem_State}
        sender-receiver-to-signal-mapping={communication-direction=IN, data-element=COMPOSITIONTYPE.RP_IF_UI2Sens02_CALID_Index_{01..16}_XIX_BMC_HV.DE_UI2Sens02_CALID_Index_{01..16}, system-signal=UI2Sens02_CALID_Index_{01..16}}
        sender-receiver-to-signal-mapping={communication-direction=IN, data-element=COMPOSITIONTYPE.RP_IF_UI2Sens02_CVN_Byte_{1..4}_XIX_BMC_HV.DE_UI2Sens02_CVN_Byte_{1..4}, system-signal=UI2Sens02_CVN_Byte_{1..4}}
        sender-receiver-to-signal-mapping={communication-direction=IN, data-element=COMPOSITIONTYPE.RP_IF_UI2Sens02_CVN_VLD_XIX_BMC_HV.DE_UI2Sens02_CVN_VLD, system-signal=UI2Sens02_CVN_VLD}
        sender-receiver-to-signal-mapping={communication-direction=IN, data-element=COMPOSITIONTYPE.RP_IF_UI2Sens02_ErrMem_State_XIX_BMC_HV.DE_UI2Sens02_ErrMem_State, system-signal=UI2Sens02_ErrMem_State}
        sender-receiver-to-signal-mapping={communication-direction=IN, data-element=COMPOSITIONTYPE.RP_IF_VDSO_Vx3d_XIX_BMC_HV.DE_VDSO_Vx3d, system-signal=VDSO_Vx3d}
        sender-receiver-to-signal-mapping={communication-direction=IN, data-element=COMPOSITIONTYPE.RP_IF_VIN_{10..17}_XIX_BMC_HV.DE_VIN_{10..17}, system-signal=VIN_{10..17}}
        sender-receiver-to-signal-mapping={communication-direction=IN, data-element=COMPOSITIONTYPE.RP_IF_VIN_{1..9}_XIX_BMC_HV.DE_VIN_{1..9}, system-signal=VIN_{1..9}}
        sender-receiver-to-signal-mapping={communication-direction=IN, data-element=COMPOSITIONTYPE.RP_IF_ZM_HV_Auszeit_HiRes_XIX_BMC_HV.DE_ZM_HV_Auszeit_HiRes, system-signal=ZM_HV_Auszeit_HiRes}
        sender-receiver-to-signal-mapping={communication-direction=IN, data-element=COMPOSITIONTYPE.RP_IF_ZM_HV_Auszeit_Status_XIX_BMC_HV.DE_ZM_HV_Auszeit_Status, system-signal=ZM_HV_Auszeit_Status}
        sender-receiver-to-signal-mapping={communication-direction=IN, data-element=COMPOSITIONTYPE.RP_IF_ZM_HV_Auszeit_XIX_BMC_HV.DE_ZM_HV_Auszeit, system-signal=ZM_HV_Auszeit}
        sender-receiver-to-signal-mapping={communication-direction=OUT, data-element=COMPOSITIONTYPE.SP_IF_KN_Hybrid_01_ECUKnockOutTimer_XIX_Infrastructure_Hybrid_01_XIX_network_infrastructure_XIX_BMC_HV.DE_KN_Hybrid_01_ECUKnockOutTimer, system-signal=KN_Hybrid_01_ECUKnockOutTimer}
        sender-receiver-to-signal-mapping={communication-direction=OUT, data-element=COMPOSITIONTYPE.SP_IF_KN_Hybrid_01_BusKnockOutTimer_XIX_Infrastructure_Hybrid_01_XIX_network_infrastructure_XIX_BMC_HV.DE_KN_Hybrid_01_BusKnockOutTimer, system-signal=KN_Hybrid_01_BusKnockOutTimer}
        sender-receiver-to-signal-mapping={communication-direction=IN, data-element=COMPOSITIONTYPE.RP_IF_DEV_Hybrid_01_Req_00_FD_Data_XIX_Infrastructure_Hybrid_01_XIX_network_infrastructure_XIX_BMC_HV.DE_DEV_Hybrid_01_Req_00_FD_Data, system-signal=DEV_Hybrid_01_Req_00_FD_Data}
        sender-receiver-to-signal-mapping={communication-direction=OUT, data-element=COMPOSITIONTYPE.SP_IF_DEV_Hybrid_01_Resp_FF_FD_Data_XIX_Infrastructure_Hybrid_01_XIX_network_infrastructure_XIX_BMC_HV.DE_DEV_Hybrid_01_Resp_FF_FD_Data, system-signal=DEV_Hybrid_01_Resp_FF_FD_Data}
        sender-receiver-to-signal-mapping={communication-direction=IN, data-element=COMPOSITIONTYPE.RP_IF_ISO_ALL_01_Req_Data_XIX_diagnosis_infrastructure_Hybrid_01_XIX_diagnosis_infrastructure_XIX_BMC_HV.DE_ISO_ALL_01_Req_Data, system-signal=ISO_ALL_01_Req_Data}
        sender-receiver-to-signal-mapping={communication-direction=OUT, data-element=COMPOSITIONTYPE.SP_IF_ISO_ALL_01_Req_Data_XIX_diagnosis_infrastructure_Hybrid_01_XIX_diagnosis_infrastructure_XIX_BMC_HV.DE_ISO_ALL_01_Req_Data, system-signal=ISO_ALL_01_Req_Data}
        sender-receiver-to-signal-mapping={data-element=RT_VehComm.COMPOSITIONTYPE.RP_BJB_ErrMem_State_1.BJB_ErrMem_State, system-signal=BJB_ErrMem_State}
        sender-receiver-to-signal-mapping={data-element=COMPOSITIONTYPE.AB_Deaktivierung_HV.AB_Deaktivierung_HV, system-signal=AB_Deaktivierung_HV}
        sender-receiver-to-signal-group-mapping={data-element=COMPOSITIONTYPE.SG_KS_Hybrid_01_Challenge_K.SG_KS_Hybrid_01_Challenge_K, signal-group=SG_KS_Hybrid_01_Challenge_K, type-mapping=sender-rec-record-type-mapping=record-element-mappings=[{application-record-element=KS_Hybrid_01_ChK, system-signal=KS_Hybrid_01_ChK}, {application-record-element=KS_Hybrid_01_ChK_IKACtr, system-signal=KS_Hybrid_01_ChK_IKACtr}, {application-record-element=KS_Hybrid_01_ChK_SID, system-signal=KS_Hybrid_01_ChK_SID}]}
        sender-receiver-to-signal-group-mapping={data-element=COMPOSITIONTYPE.SG_KS_Hybrid_01_ReqFrame.SG_KS_Hybrid_01_ReqFrame, signal-group=SG_KS_Hybrid_01_ReqFrame, type-mapping=sender-rec-record-type-mapping=record-element-mappings=[{application-record-element=KS_Hybrid_01_Req_ErrCtr, system-signal=KS_Hybrid_01_Req_ErrCtr}, {application-record-element=KS_Hybrid_01_Req_IKA_Retry, system-signal=KS_Hybrid_01_Req_IKA_Retry}, {application-record-element=KS_Hybrid_01_Req_Prio, system-signal=KS_Hybrid_01_Req_Prio}, {application-record-element=KS_Hybrid_01_Req_SID, system-signal=KS_Hybrid_01_Req_SID}, {application-record-element=KS_Hybrid_01_Req_SWMaj, system-signal=KS_Hybrid_01_Req_SWMaj}, {application-record-element=KS_Hybrid_01_Req_SWMin, system-signal=KS_Hybrid_01_Req_SWMin}, {application-record-element=KS_Hybrid_01_Req_SWPat, system-signal=KS_Hybrid_01_Req_SWPat}, {application-record-element=KS_Hybrid_01_Req_VKMS_Err, system-signal=KS_Hybrid_01_Req_VKMS_Err}]}
        sender-receiver-to-signal-group-mapping={data-element=COMPOSITIONTYPE.SG_KS_Hybrid_01_Response_K.SG_KS_Hybrid_01_Response_K, signal-group=SG_KS_Hybrid_01_Response_K, type-mapping=sender-rec-record-type-mapping=record-element-mappings=[{application-record-element=KS_Hybrid_01_ReK, system-signal=KS_Hybrid_01_ReK}, {application-record-element=KS_Hybrid_01_ReK_IKACtr, system-signal=KS_Hybrid_01_ReK_IKACtr}, {application-record-element=KS_Hybrid_01_ReK_SID, system-signal=KS_Hybrid_01_ReK_SID}]}
        sender-receiver-to-signal-group-mapping={data-element=COMPOSITIONTYPE.SG_BJB_10.SG_BJB_10, signal-group=SG_BJB_10, type-mapping=sender-rec-record-type-mapping=record-element-mappings=[{application-record-element=BJB_10_BZ, system-signal=BJB_10_BZ}, {application-record-element=BJB_10_CRC, system-signal=BJB_10_CRC}, {application-record-element=BJB_Lebensdauer_Trennelemente, system-signal=BJB_Lebensdauer_Trennelemente}, {application-record-element=BJB_Sperrung_Unterspannung, system-signal=BJB_Sperrung_Unterspannung}, {application-record-element=BJB_Status_HV_Spannungssensorik, system-signal=BJB_Status_HV_Spannungssensorik}, {application-record-element=BJB_Status_Trennelemente, system-signal=BJB_Status_Trennelemente}, {application-record-element=SignalVoid_BJB_10_0, system-signal=SignalVoid_BJB_10_0}, {application-record-element=SignalVoid_BJB_10_1, system-signal=SignalVoid_BJB_10_1}, {application-record-element=SignalVoid_BJB_10_2, system-signal=SignalVoid_BJB_10_2}, {application-record-element=SignalVoid_BJB_10_3, system-signal=SignalVoid_BJB_10_3}]}
        sender-receiver-to-signal-group-mapping={data-element=COMPOSITIONTYPE.SG_BJB_13.SG_BJB_11, signal-group=SG_BJB_11, type-mapping=sender-rec-record-type-mapping=record-element-mappings=[{application-record-element=BJB_11_BZ, system-signal=BJB_11_BZ}, {application-record-element=BJB_11_CRC, system-signal=BJB_11_CRC}, {application-record-element=BJB_Sperrung_Ueberspannung, system-signal=BJB_Sperrung_Ueberspannung}, {application-record-element=BJB_Ueberspannungszaehler_CMC01, system-signal=BJB_Ueberspannungszaehler_CMC01}, {application-record-element=BJB_Ueberspannungszaehler_CMC02, system-signal=BJB_Ueberspannungszaehler_CMC02}, {application-record-element=BJB_Uebertemperaturzaehler_CMC01, system-signal=BJB_Uebertemperaturzaehler_CMC01}, {application-record-element=BJB_Uebertemperaturzaehler_CMC02, system-signal=BJB_Uebertemperaturzaehler_CMC02}]}
        sender-receiver-to-signal-group-mapping={data-element=COMPOSITIONTYPE.SG_BJB_15.SG_BJB_12, signal-group=SG_BJB_12, type-mapping=sender-rec-record-type-mapping=record-element-mappings=[{application-record-element=BJB_12_BZ, system-signal=BJB_12_BZ}, {application-record-element=BJB_12_CRC, system-signal=BJB_12_CRC}, {application-record-element=BJB_Sperrung_Uebertemperatur, system-signal=BJB_Sperrung_Uebertemperatur}, {application-record-element=BJB_Ueberspannungszaehler_CMC03, system-signal=BJB_Ueberspannungszaehler_CMC03}, {application-record-element=BJB_Ueberspannungszaehler_CMC04, system-signal=BJB_Ueberspannungszaehler_CMC04}, {application-record-element=BJB_Uebertemperaturzaehler_CMC03, system-signal=BJB_Uebertemperaturzaehler_CMC03}, {application-record-element=BJB_Uebertemperaturzaehler_CMC04, system-signal=BJB_Uebertemperaturzaehler_CMC04}]}
        sender-receiver-to-signal-group-mapping={data-element=COMPOSITIONTYPE.SG_BJB_16.SG_BJB_13, signal-group=SG_BJB_13, type-mapping=sender-rec-record-type-mapping=record-element-mappings=[{application-record-element=BJB_13_BZ, system-signal=BJB_13_BZ}, {application-record-element=BJB_13_CRC, system-signal=BJB_13_CRC}, {application-record-element=BJB_Unterspannungszaehler_CMC01, system-signal=BJB_Unterspannungszaehler_CMC01}, {application-record-element=BJB_Unterspannungszaehler_CMC02, system-signal=BJB_Unterspannungszaehler_CMC02}, {application-record-element=BJB_Unterspannungszaehler_CMC03, system-signal=BJB_Unterspannungszaehler_CMC03}, {application-record-element=BJB_Unterspannungszaehler_CMC04, system-signal=BJB_Unterspannungszaehler_CMC04}, {application-record-element=SignalVoid_BJB_13_0, system-signal=SignalVoid_BJB_13_0}, {application-record-element=SignalVoid_BJB_13_1, system-signal=SignalVoid_BJB_13_1}]}
        sender-receiver-to-signal-group-mapping={data-element=COMPOSITIONTYPE.SG_BMC_HV_5.SG_BMC_HV_04, signal-group=SG_BMC_HV_04, type-mapping=sender-rec-record-type-mapping=record-element-mappings=[{application-record-element=BMC_Dev_Freigabe, system-signal=BMC_Dev_Freigabe}, {application-record-element=BMC_Flash_Freigabe, system-signal=BMC_Flash_Freigabe}, {application-record-element=BMC_HV_04_BZ, system-signal=BMC_HV_04_BZ}, {application-record-element=BMC_HV_04_CRC, system-signal=BMC_HV_04_CRC}, {application-record-element=BMC_Iso_Mode_Anf, system-signal=BMC_Iso_Mode_Anf}, {application-record-element=BMC_UI1_Spannung1_Schalt_Anf, system-signal=BMC_UI1_Spannung1_Schalt_Anf}, {application-record-element=BMC_UI1_Spannung2_Schalt_Anf, system-signal=BMC_UI1_Spannung2_Schalt_Anf}, {application-record-element=BMC_UI2_Spannung1_Schalt_Anf, system-signal=BMC_UI2_Spannung1_Schalt_Anf}, {application-record-element=BMC_UI2_Spannung2_Schalt_Anf, system-signal=BMC_UI2_Spannung2_Schalt_Anf}, {application-record-element=SignalVoid_BMC_HV_04_0, system-signal=SignalVoid_BMC_HV_04_0}, {application-record-element=SignalVoid_BMC_HV_04_1, system-signal=SignalVoid_BMC_HV_04_1}, {application-record-element=SignalVoid_BMC_HV_04_2, system-signal=SignalVoid_BMC_HV_04_2}, {application-record-element=SignalVoid_BMC_HV_04_3, system-signal=SignalVoid_BMC_HV_04_3}, {application-record-element=SignalVoid_BMC_HV_04_4, system-signal=SignalVoid_BMC_HV_04_4}, {application-record-element=SignalVoid_BMC_HV_04_5, system-signal=SignalVoid_BMC_HV_04_5}]}
        sender-receiver-to-signal-group-mapping={data-element=COMPOSITIONTYPE.SG_BMC_HV_17.SG_BMC_HV_10, signal-group=SG_BMC_HV_10, type-mapping=sender-rec-record-type-mapping=record-element-mappings=[{application-record-element=BMC_Datenuebernahme_Anf, system-signal=BMC_Datenuebernahme_Anf}, {application-record-element=BMC_HV_10_BZ, system-signal=BMC_HV_10_BZ}, {application-record-element=BMC_HV_10_CRC, system-signal=BMC_HV_10_CRC}, {application-record-element=BMC_Lebensdauer_Trennelemente, system-signal=BMC_Lebensdauer_Trennelemente}, {application-record-element=BMC_Sperrung_Unterspannung, system-signal=BMC_Sperrung_Unterspannung}, {application-record-element=BMC_Status_HV_Spannungssensorik, system-signal=BMC_Status_HV_Spannungssensorik}, {application-record-element=BMC_Status_Trennelemente, system-signal=BMC_Status_Trennelemente}, {application-record-element=SignalVoid_BMC_HV_10_0, system-signal=SignalVoid_BMC_HV_10_0}, {application-record-element=SignalVoid_BMC_HV_10_1, system-signal=SignalVoid_BMC_HV_10_1}, {application-record-element=SignalVoid_BMC_HV_10_2, system-signal=SignalVoid_BMC_HV_10_2}, {application-record-element=SignalVoid_BMC_HV_10_3, system-signal=SignalVoid_BMC_HV_10_3}]}
        sender-receiver-to-signal-group-mapping={data-element=COMPOSITIONTYPE.SG_BMC_HV_19.SG_BMC_HV_11, signal-group=SG_BMC_HV_11, type-mapping=sender-rec-record-type-mapping=record-element-mappings=[{application-record-element=BMC_HV_11_BZ, system-signal=BMC_HV_11_BZ}, {application-record-element=BMC_HV_11_CRC, system-signal=BMC_HV_11_CRC}, {application-record-element=BMC_Sperrung_Ueberspannung, system-signal=BMC_Sperrung_Ueberspannung}, {application-record-element=BMC_Ueberspannungszaehler_CMC01, system-signal=BMC_Ueberspannungszaehler_CMC01}, {application-record-element=BMC_Ueberspannungszaehler_CMC02, system-signal=BMC_Ueberspannungszaehler_CMC02}, {application-record-element=BMC_Uebertemperaturzaehler_CMC01, system-signal=BMC_Uebertemperaturzaehler_CMC01}, {application-record-element=BMC_Uebertemperaturzaehler_CMC02, system-signal=BMC_Uebertemperaturzaehler_CMC02}]}
        sender-receiver-to-signal-group-mapping={data-element=COMPOSITIONTYPE.SG_BMC_HV_20.SG_BMC_HV_12, signal-group=SG_BMC_HV_12, type-mapping=sender-rec-record-type-mapping=record-element-mappings=[{application-record-element=BMC_HV_12_BZ, system-signal=BMC_HV_12_BZ}, {application-record-element=BMC_HV_12_CRC, system-signal=BMC_HV_12_CRC}, {application-record-element=BMC_Sperrung_Uebertemperatur, system-signal=BMC_Sperrung_Uebertemperatur}, {application-record-element=BMC_Ueberspannungszaehler_CMC03, system-signal=BMC_Ueberspannungszaehler_CMC03}, {application-record-element=BMC_Ueberspannungszaehler_CMC04, system-signal=BMC_Ueberspannungszaehler_CMC04}, {application-record-element=BMC_Uebertemperaturzaehler_CMC03, system-signal=BMC_Uebertemperaturzaehler_CMC03}, {application-record-element=BMC_Uebertemperaturzaehler_CMC04, system-signal=BMC_Uebertemperaturzaehler_CMC04}]}
        sender-receiver-to-signal-group-mapping={data-element=COMPOSITIONTYPE.SG_BMC_HV_21.SG_BMC_HV_13, signal-group=SG_BMC_HV_13, type-mapping=sender-rec-record-type-mapping=record-element-mappings=[{application-record-element=BMC_HV_13_BZ, system-signal=BMC_HV_13_BZ}, {application-record-element=BMC_HV_13_CRC, system-signal=BMC_HV_13_CRC}, {application-record-element=BMC_Unterspannungszaehler_CMC01, system-signal=BMC_Unterspannungszaehler_CMC01}, {application-record-element=BMC_Unterspannungszaehler_CMC02, system-signal=BMC_Unterspannungszaehler_CMC02}, {application-record-element=BMC_Unterspannungszaehler_CMC03, system-signal=BMC_Unterspannungszaehler_CMC03}, {application-record-element=BMC_Unterspannungszaehler_CMC04, system-signal=BMC_Unterspannungszaehler_CMC04}, {application-record-element=SignalVoid_BMC_HV_13_0, system-signal=SignalVoid_BMC_HV_13_0}, {application-record-element=SignalVoid_BMC_HV_13_1, system-signal=SignalVoid_BMC_HV_13_1}]}
        sender-receiver-to-signal-mapping={data-element=COMPOSITIONTYPE.Vishnu_Test_100Bytes_PDU_NewSignal5_2a9e79b5a4a81ebd.Vishnu_Test_100Bytes_PDU_NewSignal5_2a9e79b5a4a81ebd, system-signal=Vishnu_Test_100Bytes_PDU_NewSignal5_2a9e79b5a4a81ebd}
        sender-receiver-to-signal-mapping={data-element=COMPOSITIONTYPE.DTC_Test_PDU_Set_Signal_e68158b3301efab7.DTC_Test_PDU_Set_Signal_e68158b3301efab7, system-signal=DTC_Test_PDU_Set_Signal_e68158b3301efab7}
      sw-mappings:
        15 x swc to ecu mapping, all with ecu-instance=BMC_HV:
          MAPPING_BMC_Berechnung_SOC_XIX_SoC_XIX_BMC_HV  # UB:Derived from original system description
          MAPPING_BMC_HVS_Slave_XIX_SoC_XIX_BMC_HV  # UB:Derived from original system description
          MAPPING_BMC_HV_Netzsteuerung_XIX_NV_SD_XIX_BMC_HV  # UB:Derived from original system description
          MAPPING_BMC_SafetyDataStorage_XIX_SoC_XIX_BMC_HV  # UB:Derived from original system description
          MAPPING_DaapServer_BMC_HV_XIX_GDC_DAAP_XIX_BMC_HV  # UB:Derived from original system description
          MAPPING_HVB_Fehlerausgabe_SecondaryOBDECU_XIX_SoC_XIX_BMC_HV  # UB:Derived from original system description
          MAPPING_HV_Batterie_RTM_XIX_RTM_XIX_BMC_HV  # UB:Derived from original system description
          MAPPING_HochvoltBatterieManagement_XIX_SoC_XIX_BMC_HV  # UB:Derived from original system description
          MAPPING_Infrastructure_Hybrid_01_XIX_network_infrastructure_XIX_BMC_HV  # UB:Derived from original system description
          MAPPING_KS_BMC_HV_XIX_KSGen3_XIX_BMC_HV  # UB:Derived from original system description
          MAPPING_ORU_Infrastructure_Hybrid_01_XIX_ORU6_XIX_BMC_HV  # UB:Derived from original system description
          MAPPING_OTA_Infrastructure_Hybrid_01_XIX_ORU6_XIX_BMC_HV  # UB:Derived from original system description
          MAPPING_SOK_Participant_BMC_HV_XIX_SOK_XIX_BMC_HV  # UB:Derived from original system description
          MAPPING_VKMS_Participant_BMC_HV_XIX_VKMS_XIX_BMC_HV  # UB:Derived from original system description
          MAPPING_diagnosis_infrastructure_Hybrid_01_XIX_diagnosis_infrastructure_XIX_BMC_HV  # UB:Derived from original system description
    root-software-compositions:
      root sw composition prototype COMPOSITIONTYPE: flat-map=FLATMAP, software-composition=COMPOSITIONTYPE
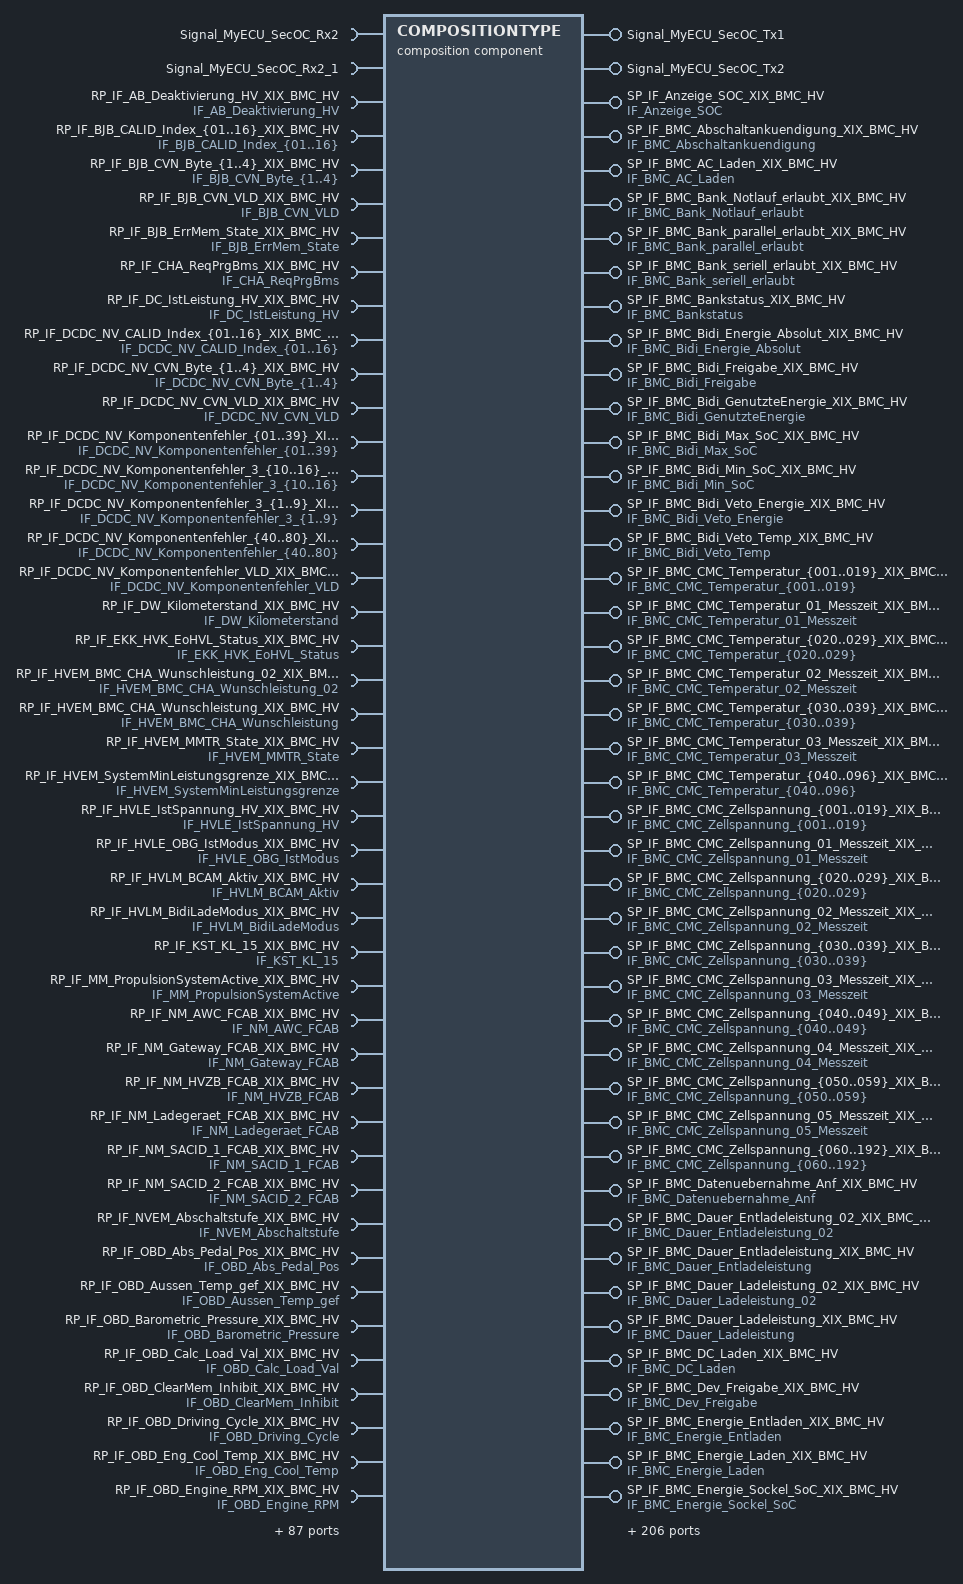
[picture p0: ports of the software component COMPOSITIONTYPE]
  composition sw component type COMPOSITIONTYPE  # UB:Derived from original system description
    provide port Signal_MyECU_SecOC_Tx1: nonqueued-sender-com-spec{data-element=Signal_MyECU_SecOC_Tx1, init-value=0}, provided-interface=Signal_MyECU_SecOC_Tx1
    provide port Signal_MyECU_SecOC_Tx2: nonqueued-sender-com-spec{data-element=Signal_MyECU_SecOC_Tx2, init-value=0}, provided-interface=Signal_MyECU_SecOC_Tx2
    require port Signal_MyECU_SecOC_Rx2: nonqueued-receiver-com-spec{data-element=Signal_MyECU_SecOC_Rx2, init-value=0}, required-interface=Signal_MyECU_SecOC_Rx2
    require port Signal_MyECU_SecOC_Rx2_1: nonqueued-receiver-com-spec{data-element=Signal_MyECU_SecOC_Rx2, init-value=0}, required-interface=Signal_MyECU_SecOC_Rx2_1
    519 x provide port:
      SP_IF_Anzeige_SOC_XIX_BMC_HV: nonqueued-sender-com-spec=DE_Anzeige_SOC, provided-interface=IF_Anzeige_SOC
      SP_IF_BMC_Abschaltankuendigung_XIX_BMC_HV: nonqueued-sender-com-spec=DE_BMC_Abschaltankuendigung, provided-interface=IF_BMC_Abschaltankuendigung
      SP_IF_BMC_AC_Laden_XIX_BMC_HV: nonqueued-sender-com-spec=DE_BMC_AC_Laden, provided-interface=IF_BMC_AC_Laden
      SP_IF_BMC_Bank_Notlauf_erlaubt_XIX_BMC_HV: nonqueued-sender-com-spec=DE_BMC_Bank_Notlauf_erlaubt, provided-interface=IF_BMC_Bank_Notlauf_erlaubt
      SP_IF_BMC_Bank_parallel_erlaubt_XIX_BMC_HV: nonqueued-sender-com-spec=DE_BMC_Bank_parallel_erlaubt, provided-interface=IF_BMC_Bank_parallel_erlaubt
      SP_IF_BMC_Bank_seriell_erlaubt_XIX_BMC_HV: nonqueued-sender-com-spec=DE_BMC_Bank_seriell_erlaubt, provided-interface=IF_BMC_Bank_seriell_erlaubt
      SP_IF_BMC_Bankstatus_XIX_BMC_HV: nonqueued-sender-com-spec=DE_BMC_Bankstatus, provided-interface=IF_BMC_Bankstatus
      SP_IF_BMC_Bidi_Energie_Absolut_XIX_BMC_HV: nonqueued-sender-com-spec=DE_BMC_Bidi_Energie_Absolut, provided-interface=IF_BMC_Bidi_Energie_Absolut
      SP_IF_BMC_Bidi_Freigabe_XIX_BMC_HV: nonqueued-sender-com-spec=DE_BMC_Bidi_Freigabe, provided-interface=IF_BMC_Bidi_Freigabe
      SP_IF_BMC_Bidi_GenutzteEnergie_XIX_BMC_HV: nonqueued-sender-com-spec=DE_BMC_Bidi_GenutzteEnergie, provided-interface=IF_BMC_Bidi_GenutzteEnergie
      SP_IF_BMC_Bidi_Max_SoC_XIX_BMC_HV: nonqueued-sender-com-spec=DE_BMC_Bidi_Max_SoC, provided-interface=IF_BMC_Bidi_Max_SoC
      SP_IF_BMC_Bidi_Min_SoC_XIX_BMC_HV: nonqueued-sender-com-spec=DE_BMC_Bidi_Min_SoC, provided-interface=IF_BMC_Bidi_Min_SoC
      SP_IF_BMC_Bidi_Veto_Energie_XIX_BMC_HV: nonqueued-sender-com-spec=DE_BMC_Bidi_Veto_Energie, provided-interface=IF_BMC_Bidi_Veto_Energie
      SP_IF_BMC_Bidi_Veto_Temp_XIX_BMC_HV: nonqueued-sender-com-spec=DE_BMC_Bidi_Veto_Temp, provided-interface=IF_BMC_Bidi_Veto_Temp
      SP_IF_BMC_CMC_Temperatur_{001..019}_XIX_BMC_HV: nonqueued-sender-com-spec=DE_BMC_CMC_Temperatur_{001..019}, provided-interface=IF_BMC_CMC_Temperatur_{001..019}
      SP_IF_BMC_CMC_Temperatur_01_Messzeit_XIX_BMC_HV: nonqueued-sender-com-spec=DE_BMC_CMC_Temperatur_01_Messzeit, provided-interface=IF_BMC_CMC_Temperatur_01_Messzeit
      SP_IF_BMC_CMC_Temperatur_{020..029}_XIX_BMC_HV: nonqueued-sender-com-spec=DE_BMC_CMC_Temperatur_{020..029}, provided-interface=IF_BMC_CMC_Temperatur_{020..029}
      SP_IF_BMC_CMC_Temperatur_02_Messzeit_XIX_BMC_HV: nonqueued-sender-com-spec=DE_BMC_CMC_Temperatur_02_Messzeit, provided-interface=IF_BMC_CMC_Temperatur_02_Messzeit
      SP_IF_BMC_CMC_Temperatur_{030..039}_XIX_BMC_HV: nonqueued-sender-com-spec=DE_BMC_CMC_Temperatur_{030..039}, provided-interface=IF_BMC_CMC_Temperatur_{030..039}
      SP_IF_BMC_CMC_Temperatur_03_Messzeit_XIX_BMC_HV: nonqueued-sender-com-spec=DE_BMC_CMC_Temperatur_03_Messzeit, provided-interface=IF_BMC_CMC_Temperatur_03_Messzeit
      SP_IF_BMC_CMC_Temperatur_{040..096}_XIX_BMC_HV: nonqueued-sender-com-spec=DE_BMC_CMC_Temperatur_{040..096}, provided-interface=IF_BMC_CMC_Temperatur_{040..096}
      SP_IF_BMC_CMC_Zellspannung_{001..019}_XIX_BMC_HV: nonqueued-sender-com-spec=DE_BMC_CMC_Zellspannung_{001..019}, provided-interface=IF_BMC_CMC_Zellspannung_{001..019}
      SP_IF_BMC_CMC_Zellspannung_01_Messzeit_XIX_BMC_HV: nonqueued-sender-com-spec=DE_BMC_CMC_Zellspannung_01_Messzeit, provided-interface=IF_BMC_CMC_Zellspannung_01_Messzeit
      SP_IF_BMC_CMC_Zellspannung_{020..029}_XIX_BMC_HV: nonqueued-sender-com-spec=DE_BMC_CMC_Zellspannung_{020..029}, provided-interface=IF_BMC_CMC_Zellspannung_{020..029}
      SP_IF_BMC_CMC_Zellspannung_02_Messzeit_XIX_BMC_HV: nonqueued-sender-com-spec=DE_BMC_CMC_Zellspannung_02_Messzeit, provided-interface=IF_BMC_CMC_Zellspannung_02_Messzeit
      SP_IF_BMC_CMC_Zellspannung_{030..039}_XIX_BMC_HV: nonqueued-sender-com-spec=DE_BMC_CMC_Zellspannung_{030..039}, provided-interface=IF_BMC_CMC_Zellspannung_{030..039}
      SP_IF_BMC_CMC_Zellspannung_03_Messzeit_XIX_BMC_HV: nonqueued-sender-com-spec=DE_BMC_CMC_Zellspannung_03_Messzeit, provided-interface=IF_BMC_CMC_Zellspannung_03_Messzeit
      SP_IF_BMC_CMC_Zellspannung_{040..049}_XIX_BMC_HV: nonqueued-sender-com-spec=DE_BMC_CMC_Zellspannung_{040..049}, provided-interface=IF_BMC_CMC_Zellspannung_{040..049}
      SP_IF_BMC_CMC_Zellspannung_04_Messzeit_XIX_BMC_HV: nonqueued-sender-com-spec=DE_BMC_CMC_Zellspannung_04_Messzeit, provided-interface=IF_BMC_CMC_Zellspannung_04_Messzeit
      SP_IF_BMC_CMC_Zellspannung_{050..059}_XIX_BMC_HV: nonqueued-sender-com-spec=DE_BMC_CMC_Zellspannung_{050..059}, provided-interface=IF_BMC_CMC_Zellspannung_{050..059}
      SP_IF_BMC_CMC_Zellspannung_05_Messzeit_XIX_BMC_HV: nonqueued-sender-com-spec=DE_BMC_CMC_Zellspannung_05_Messzeit, provided-interface=IF_BMC_CMC_Zellspannung_05_Messzeit
      SP_IF_BMC_CMC_Zellspannung_{060..192}_XIX_BMC_HV: nonqueued-sender-com-spec=DE_BMC_CMC_Zellspannung_{060..192}, provided-interface=IF_BMC_CMC_Zellspannung_{060..192}
      SP_IF_BMC_Datenuebernahme_Anf_XIX_BMC_HV: nonqueued-sender-com-spec=DE_BMC_Datenuebernahme_Anf, provided-interface=IF_BMC_Datenuebernahme_Anf
      SP_IF_BMC_Dauer_Entladeleistung_02_XIX_BMC_HV: nonqueued-sender-com-spec=DE_BMC_Dauer_Entladeleistung_02, provided-interface=IF_BMC_Dauer_Entladeleistung_02
      SP_IF_BMC_Dauer_Entladeleistung_XIX_BMC_HV: nonqueued-sender-com-spec=DE_BMC_Dauer_Entladeleistung, provided-interface=IF_BMC_Dauer_Entladeleistung
      SP_IF_BMC_Dauer_Ladeleistung_02_XIX_BMC_HV: nonqueued-sender-com-spec=DE_BMC_Dauer_Ladeleistung_02, provided-interface=IF_BMC_Dauer_Ladeleistung_02
      SP_IF_BMC_Dauer_Ladeleistung_XIX_BMC_HV: nonqueued-sender-com-spec=DE_BMC_Dauer_Ladeleistung, provided-interface=IF_BMC_Dauer_Ladeleistung
      SP_IF_BMC_DC_Laden_XIX_BMC_HV: nonqueued-sender-com-spec=DE_BMC_DC_Laden, provided-interface=IF_BMC_DC_Laden
      SP_IF_BMC_Dev_Freigabe_XIX_BMC_HV: nonqueued-sender-com-spec=DE_BMC_Dev_Freigabe, provided-interface=IF_BMC_Dev_Freigabe
      SP_IF_BMC_Energie_Entladen_XIX_BMC_HV: nonqueued-sender-com-spec=DE_BMC_Energie_Entladen, provided-interface=IF_BMC_Energie_Entladen
      SP_IF_BMC_Energie_Laden_XIX_BMC_HV: nonqueued-sender-com-spec=DE_BMC_Energie_Laden, provided-interface=IF_BMC_Energie_Laden
      SP_IF_BMC_Energie_Sockel_SoC_XIX_BMC_HV: nonqueued-sender-com-spec=DE_BMC_Energie_Sockel_SoC, provided-interface=IF_BMC_Energie_Sockel_SoC
      SP_IF_BMC_Energieinhalt_XIX_BMC_HV: nonqueued-sender-com-spec=DE_BMC_Energieinhalt, provided-interface=IF_BMC_Energieinhalt
      SP_IF_BMC_EnergieVorhalt_XIX_BMC_HV: nonqueued-sender-com-spec=DE_BMC_EnergieVorhalt, provided-interface=IF_BMC_EnergieVorhalt
      SP_IF_BMC_ExtLadeleistung_XIX_BMC_HV: nonqueued-sender-com-spec=DE_BMC_ExtLadeleistung, provided-interface=IF_BMC_ExtLadeleistung
      SP_IF_BMC_Fehler_Leistungsred_XIX_BMC_HV: nonqueued-sender-com-spec=DE_BMC_Fehler_Leistungsred, provided-interface=IF_BMC_Fehler_Leistungsred
      SP_IF_BMC_Fehler_Warnung_XIX_BMC_HV: nonqueued-sender-com-spec=DE_BMC_Fehler_Warnung, provided-interface=IF_BMC_Fehler_Warnung
      SP_IF_BMC_Flash_Freigabe_XIX_BMC_HV: nonqueued-sender-com-spec=DE_BMC_Flash_Freigabe, provided-interface=IF_BMC_Flash_Freigabe
      SP_IF_BMC_HV_01_BZ_XIX_BMC_HV: nonqueued-sender-com-spec=DE_BMC_HV_01_BZ, provided-interface=IF_BMC_HV_01_BZ
      SP_IF_BMC_HV_01_CRC_XIX_BMC_HV: nonqueued-sender-com-spec=DE_BMC_HV_01_CRC, provided-interface=IF_BMC_HV_01_CRC
      SP_IF_BMC_HV_02_BZ_XIX_BMC_HV: nonqueued-sender-com-spec=DE_BMC_HV_02_BZ, provided-interface=IF_BMC_HV_02_BZ
      SP_IF_BMC_HV_02_CRC_XIX_BMC_HV: nonqueued-sender-com-spec=DE_BMC_HV_02_CRC, provided-interface=IF_BMC_HV_02_CRC
      SP_IF_BMC_HV_04_BZ_XIX_BMC_HV: nonqueued-sender-com-spec=DE_BMC_HV_04_BZ, provided-interface=IF_BMC_HV_04_BZ
      SP_IF_BMC_HV_04_CRC_XIX_BMC_HV: nonqueued-sender-com-spec=DE_BMC_HV_04_CRC, provided-interface=IF_BMC_HV_04_CRC
      SP_IF_BMC_HV_10_BZ_XIX_BMC_HV: nonqueued-sender-com-spec=DE_BMC_HV_10_BZ, provided-interface=IF_BMC_HV_10_BZ
      SP_IF_BMC_HV_10_CRC_XIX_BMC_HV: nonqueued-sender-com-spec=DE_BMC_HV_10_CRC, provided-interface=IF_BMC_HV_10_CRC
      SP_IF_BMC_HV_11_BZ_XIX_BMC_HV: nonqueued-sender-com-spec=DE_BMC_HV_11_BZ, provided-interface=IF_BMC_HV_11_BZ
      SP_IF_BMC_HV_11_CRC_XIX_BMC_HV: nonqueued-sender-com-spec=DE_BMC_HV_11_CRC, provided-interface=IF_BMC_HV_11_CRC
      SP_IF_BMC_HV_12_BZ_XIX_BMC_HV: nonqueued-sender-com-spec=DE_BMC_HV_12_BZ, provided-interface=IF_BMC_HV_12_BZ
      SP_IF_BMC_HV_12_CRC_XIX_BMC_HV: nonqueued-sender-com-spec=DE_BMC_HV_12_CRC, provided-interface=IF_BMC_HV_12_CRC
      SP_IF_BMC_HV_13_BZ_XIX_BMC_HV: nonqueued-sender-com-spec=DE_BMC_HV_13_BZ, provided-interface=IF_BMC_HV_13_BZ
      SP_IF_BMC_HV_13_CRC_XIX_BMC_HV: nonqueued-sender-com-spec=DE_BMC_HV_13_CRC, provided-interface=IF_BMC_HV_13_CRC
      SP_IF_BMC_HVK_EoHVL_Status_XIX_BMC_HV: nonqueued-sender-com-spec=DE_BMC_HVK_EoHVL_Status, provided-interface=IF_BMC_HVK_EoHVL_Status
      SP_IF_BMC_HVK_Fehler_HVIL_XIX_BMC_HV: nonqueued-sender-com-spec=DE_BMC_HVK_Fehler_HVIL, provided-interface=IF_BMC_HVK_Fehler_HVIL
      SP_IF_BMC_HVK_Fehler_Intern_XIX_BMC_HV: nonqueued-sender-com-spec=DE_BMC_HVK_Fehler_Intern, provided-interface=IF_BMC_HVK_Fehler_Intern
      SP_IF_BMC_HVK_Fehler_SD_XIX_BMC_HV: nonqueued-sender-com-spec=DE_BMC_HVK_Fehler_SD, provided-interface=IF_BMC_HVK_Fehler_SD
      SP_IF_BMC_Iso_Mode_Anf_XIX_BMC_HV: nonqueued-sender-com-spec=DE_BMC_Iso_Mode_Anf, provided-interface=IF_BMC_Iso_Mode_Anf
      SP_IF_BMC_IstTemperaturMax_Modul_ID_XIX_BMC_HV: nonqueued-sender-com-spec=DE_BMC_IstTemperaturMax_Modul_ID, provided-interface=IF_BMC_IstTemperaturMax_Modul_ID
      SP_IF_BMC_IstTemperaturMax_Sensor_ID_XIX_BMC_HV: nonqueued-sender-com-spec=DE_BMC_IstTemperaturMax_Sensor_ID, provided-interface=IF_BMC_IstTemperaturMax_Sensor_ID
      SP_IF_BMC_IstTemperaturMin_Modul_ID_XIX_BMC_HV: nonqueued-sender-com-spec=DE_BMC_IstTemperaturMin_Modul_ID, provided-interface=IF_BMC_IstTemperaturMin_Modul_ID
      SP_IF_BMC_IstTemperaturMin_Sensor_ID_XIX_BMC_HV: nonqueued-sender-com-spec=DE_BMC_IstTemperaturMin_Sensor_ID, provided-interface=IF_BMC_IstTemperaturMin_Sensor_ID
      SP_IF_BMC_IstZellSpannungMax_Modul_ID_XIX_BMC_HV: nonqueued-sender-com-spec=DE_BMC_IstZellSpannungMax_Modul_ID, provided-interface=IF_BMC_IstZellSpannungMax_Modul_ID
      SP_IF_BMC_IstZellspannungMax_XIX_BMC_HV: nonqueued-sender-com-spec=DE_BMC_IstZellspannungMax, provided-interface=IF_BMC_IstZellspannungMax
      SP_IF_BMC_IstZellSpannungMax_Zell_ID_XIX_BMC_HV: nonqueued-sender-com-spec=DE_BMC_IstZellSpannungMax_Zell_ID, provided-interface=IF_BMC_IstZellSpannungMax_Zell_ID
      SP_IF_BMC_IstZellSpannungMin_Modul_ID_XIX_BMC_HV: nonqueued-sender-com-spec=DE_BMC_IstZellSpannungMin_Modul_ID, provided-interface=IF_BMC_IstZellSpannungMin_Modul_ID
      SP_IF_BMC_IstZellspannungMin_XIX_BMC_HV: nonqueued-sender-com-spec=DE_BMC_IstZellspannungMin, provided-interface=IF_BMC_IstZellspannungMin
      SP_IF_BMC_IstZellSpannungMin_Zell_ID_XIX_BMC_HV: nonqueued-sender-com-spec=DE_BMC_IstZellSpannungMin_Zell_ID, provided-interface=IF_BMC_IstZellSpannungMin_Zell_ID
      SP_IF_BMC_IWU_Status_XIX_BMC_HV: nonqueued-sender-com-spec=DE_BMC_IWU_Status, provided-interface=IF_BMC_IWU_Status
      SP_IF_BMC_IWU_Wert_neg_XIX_BMC_HV: nonqueued-sender-com-spec=DE_BMC_IWU_Wert_neg, provided-interface=IF_BMC_IWU_Wert_neg
      SP_IF_BMC_IWU_Wert_pos_XIX_BMC_HV: nonqueued-sender-com-spec=DE_BMC_IWU_Wert_pos, provided-interface=IF_BMC_IWU_Wert_pos
      SP_IF_BMC_Konditionierung_Anf_XIX_BMC_HV: nonqueued-sender-com-spec=DE_BMC_Konditionierung_Anf, provided-interface=IF_BMC_Konditionierung_Anf
      SP_IF_BMC_KundenWarnung_XIX_BMC_HV: nonqueued-sender-com-spec=DE_BMC_KundenWarnung, provided-interface=IF_BMC_KundenWarnung
      SP_IF_BMC_Lebensdauer_Trennelemente_XIX_BMC_HV: nonqueued-sender-com-spec=DE_BMC_Lebensdauer_Trennelemente, provided-interface=IF_BMC_Lebensdauer_Trennelemente
      SP_IF_BMC_Leerlaufspannung_XIX_BMC_HV: nonqueued-sender-com-spec=DE_BMC_Leerlaufspannung, provided-interface=IF_BMC_Leerlaufspannung
      SP_IF_BMC_Max_Entladeleistung_02_XIX_BMC_HV: nonqueued-sender-com-spec=DE_BMC_Max_Entladeleistung_02, provided-interface=IF_BMC_Max_Entladeleistung_02
      SP_IF_BMC_Max_Entladeleistung_XIX_BMC_HV: nonqueued-sender-com-spec=DE_BMC_Max_Entladeleistung, provided-interface=IF_BMC_Max_Entladeleistung
      SP_IF_BMC_Max_Entladestrom_02_XIX_BMC_HV: nonqueued-sender-com-spec=DE_BMC_Max_Entladestrom_02, provided-interface=IF_BMC_Max_Entladestrom_02
      SP_IF_BMC_Max_Entladestrom_XIX_BMC_HV: nonqueued-sender-com-spec=DE_BMC_Max_Entladestrom, provided-interface=IF_BMC_Max_Entladestrom
      SP_IF_BMC_Max_Ladeleistung_02_XIX_BMC_HV: nonqueued-sender-com-spec=DE_BMC_Max_Ladeleistung_02, provided-interface=IF_BMC_Max_Ladeleistung_02
      SP_IF_BMC_Max_Ladeleistung_XIX_BMC_HV: nonqueued-sender-com-spec=DE_BMC_Max_Ladeleistung, provided-interface=IF_BMC_Max_Ladeleistung
      SP_IF_BMC_Max_Ladestrom_02_XIX_BMC_HV: nonqueued-sender-com-spec=DE_BMC_Max_Ladestrom_02, provided-interface=IF_BMC_Max_Ladestrom_02
      SP_IF_BMC_Max_Ladestrom_XIX_BMC_HV: nonqueued-sender-com-spec=DE_BMC_Max_Ladestrom, provided-interface=IF_BMC_Max_Ladestrom
      SP_IF_BMC_Max_Spannung_XIX_BMC_HV: nonqueued-sender-com-spec=DE_BMC_Max_Spannung, provided-interface=IF_BMC_Max_Spannung
      SP_IF_BMC_MaxEnergieinhalt_XIX_BMC_HV: nonqueued-sender-com-spec=DE_BMC_MaxEnergieinhalt, provided-interface=IF_BMC_MaxEnergieinhalt
      SP_IF_BMC_Min_Spannung_XIX_BMC_HV: nonqueued-sender-com-spec=DE_BMC_Min_Spannung, provided-interface=IF_BMC_Min_Spannung
      SP_IF_BMC_MinDyn_Entladespannung_XIX_BMC_HV: nonqueued-sender-com-spec=DE_BMC_MinDyn_Entladespannung, provided-interface=IF_BMC_MinDyn_Entladespannung
      SP_IF_BMC_MinDyn_Ladespannung_XIX_BMC_HV: nonqueued-sender-com-spec=DE_BMC_MinDyn_Ladespannung, provided-interface=IF_BMC_MinDyn_Ladespannung
      SP_IF_BMC_MMTR_Status_XIX_BMC_HV: nonqueued-sender-com-spec=DE_BMC_MMTR_Status, provided-interface=IF_BMC_MMTR_Status
      SP_IF_BMC_Modus_XIX_BMC_HV: nonqueued-sender-com-spec=DE_BMC_Modus, provided-interface=IF_BMC_Modus
      SP_IF_BMC_NutzbareKapazitaet_XIX_BMC_HV: nonqueued-sender-com-spec=DE_BMC_NutzbareKapazitaet, provided-interface=IF_BMC_NutzbareKapazitaet
      SP_IF_BMC_NutzbarerSOC_XIX_BMC_HV: nonqueued-sender-com-spec=DE_BMC_NutzbarerSOC, provided-interface=IF_BMC_NutzbarerSOC
      SP_IF_BMC_Pack_SN_{01..26}_XIX_BMC_HV: nonqueued-sender-com-spec=DE_BMC_Pack_SN_{01..26}, provided-interface=IF_BMC_Pack_SN_{01..26}
      SP_IF_BMC_PCM_VTD_Freeze_Req_XIX_BMC_HV: nonqueued-sender-com-spec=DE_BMC_PCM_VTD_Freeze_Req, provided-interface=IF_BMC_PCM_VTD_Freeze_Req
      SP_IF_BMC_PCM_VTD_LifeTimeReset_Req_XIX_BMC_HV: nonqueued-sender-com-spec=DE_BMC_PCM_VTD_LifeTimeReset_Req, provided-interface=IF_BMC_PCM_VTD_LifeTimeReset_Req
      SP_IF_BMC_PCM_VTD_LifeTimeReset_Resp_XIX_BMC_HV: nonqueued-sender-com-spec=DE_BMC_PCM_VTD_LifeTimeReset_Resp, provided-interface=IF_BMC_PCM_VTD_LifeTimeReset_Resp
      SP_IF_BMC_PCM_VTD_RecentReset_Req_XIX_BMC_HV: nonqueued-sender-com-spec=DE_BMC_PCM_VTD_RecentReset_Req, provided-interface=IF_BMC_PCM_VTD_RecentReset_Req
      SP_IF_BMC_PerfInd_Entladen_XIX_BMC_HV: nonqueued-sender-com-spec=DE_BMC_PerfInd_Entladen, provided-interface=IF_BMC_PerfInd_Entladen
      SP_IF_BMC_PerfInd_Laden_XIX_BMC_HV: nonqueued-sender-com-spec=DE_BMC_PerfInd_Laden, provided-interface=IF_BMC_PerfInd_Laden
      SP_IF_BMC_PredLeistung_StuetzungNV_XIX_BMC_HV: nonqueued-sender-com-spec=DE_BMC_PredLeistung_StuetzungNV, provided-interface=IF_BMC_PredLeistung_StuetzungNV
      SP_IF_BMC_Range_Indikator_XIX_BMC_HV: nonqueued-sender-com-spec=DE_BMC_Range_Indikator, provided-interface=IF_BMC_Range_Indikator
      SP_IF_BMC_Rekuperation_Ueberlauf_XIX_BMC_HV: nonqueued-sender-com-spec=DE_BMC_Rekuperation_Ueberlauf, provided-interface=IF_BMC_Rekuperation_Ueberlauf
      SP_IF_BMC_Rekuperation_XIX_BMC_HV: nonqueued-sender-com-spec=DE_BMC_Rekuperation, provided-interface=IF_BMC_Rekuperation
      SP_IF_BMC_RtmWarnBattUnautorisiert_XIX_BMC_HV: nonqueued-sender-com-spec=DE_BMC_RtmWarnBattUnautorisiert, provided-interface=IF_BMC_RtmWarnBattUnautorisiert
      SP_IF_BMC_RtmWarnPackKommunikation_XIX_BMC_HV: nonqueued-sender-com-spec=DE_BMC_RtmWarnPackKommunikation, provided-interface=IF_BMC_RtmWarnPackKommunikation
      SP_IF_BMC_RtmWarnPackUeberladen_XIX_BMC_HV: nonqueued-sender-com-spec=DE_BMC_RtmWarnPackUeberladen, provided-interface=IF_BMC_RtmWarnPackUeberladen
      SP_IF_BMC_RtmWarnSocHoch_XIX_BMC_HV: nonqueued-sender-com-spec=DE_BMC_RtmWarnSocHoch, provided-interface=IF_BMC_RtmWarnSocHoch
      SP_IF_BMC_RtmWarnSocNiedrig_XIX_BMC_HV: nonqueued-sender-com-spec=DE_BMC_RtmWarnSocNiedrig, provided-interface=IF_BMC_RtmWarnSocNiedrig
      SP_IF_BMC_RtmWarnSocSprung_XIX_BMC_HV: nonqueued-sender-com-spec=DE_BMC_RtmWarnSocSprung, provided-interface=IF_BMC_RtmWarnSocSprung
      SP_IF_BMC_RtmWarnTZelleDiff_XIX_BMC_HV: nonqueued-sender-com-spec=DE_BMC_RtmWarnTZelleDiff, provided-interface=IF_BMC_RtmWarnTZelleDiff
      SP_IF_BMC_RtmWarnTZelleMax_XIX_BMC_HV: nonqueued-sender-com-spec=DE_BMC_RtmWarnTZelleMax, provided-interface=IF_BMC_RtmWarnTZelleMax
      SP_IF_BMC_RtmWarnTZelleMin_XIX_BMC_HV: nonqueued-sender-com-spec=DE_BMC_RtmWarnTZelleMin, provided-interface=IF_BMC_RtmWarnTZelleMin
      SP_IF_BMC_RtmWarnUeberstrom_XIX_BMC_HV: nonqueued-sender-com-spec=DE_BMC_RtmWarnUeberstrom, provided-interface=IF_BMC_RtmWarnUeberstrom
      SP_IF_BMC_RtmWarnUPackMax_XIX_BMC_HV: nonqueued-sender-com-spec=DE_BMC_RtmWarnUPackMax, provided-interface=IF_BMC_RtmWarnUPackMax
      SP_IF_BMC_RtmWarnUPackMin_XIX_BMC_HV: nonqueued-sender-com-spec=DE_BMC_RtmWarnUPackMin, provided-interface=IF_BMC_RtmWarnUPackMin
      SP_IF_BMC_RtmWarnUZelleMax_XIX_BMC_HV: nonqueued-sender-com-spec=DE_BMC_RtmWarnUZelleMax, provided-interface=IF_BMC_RtmWarnUZelleMax
      SP_IF_BMC_RtmWarnUZelleMin_XIX_BMC_HV: nonqueued-sender-com-spec=DE_BMC_RtmWarnUZelleMin, provided-interface=IF_BMC_RtmWarnUZelleMin
      SP_IF_BMC_RtmWarnZelleZustand_XIX_BMC_HV: nonqueued-sender-com-spec=DE_BMC_RtmWarnZelleZustand, provided-interface=IF_BMC_RtmWarnZelleZustand
      SP_IF_BMC_RuecklaufTemperatur_XIX_BMC_HV: nonqueued-sender-com-spec=DE_BMC_RuecklaufTemperatur, provided-interface=IF_BMC_RuecklaufTemperatur
      SP_IF_BMC_Spannung_DC_Ladesaeule_XIX_BMC_HV: nonqueued-sender-com-spec=DE_BMC_Spannung_DC_Ladesaeule, provided-interface=IF_BMC_Spannung_DC_Ladesaeule
      SP_IF_BMC_Spannung_Messzeit_XIX_BMC_HV: nonqueued-sender-com-spec=DE_BMC_Spannung_Messzeit, provided-interface=IF_BMC_Spannung_Messzeit
      SP_IF_BMC_Spannung_XIX_BMC_HV: nonqueued-sender-com-spec=DE_BMC_Spannung, provided-interface=IF_BMC_Spannung
      SP_IF_BMC_Spannung_ZwischenKreis_2_XIX_BMC_HV: nonqueued-sender-com-spec=DE_BMC_Spannung_ZwischenKreis_2, provided-interface=IF_BMC_Spannung_ZwischenKreis_2
      SP_IF_BMC_Spannung_ZwischenKreis_XIX_BMC_HV: nonqueued-sender-com-spec=DE_BMC_Spannung_ZwischenKreis, provided-interface=IF_BMC_Spannung_ZwischenKreis
      SP_IF_BMC_Sperrung_Ueberspannung_XIX_BMC_HV: nonqueued-sender-com-spec=DE_BMC_Sperrung_Ueberspannung, provided-interface=IF_BMC_Sperrung_Ueberspannung
      SP_IF_BMC_Sperrung_Uebertemperatur_XIX_BMC_HV: nonqueued-sender-com-spec=DE_BMC_Sperrung_Uebertemperatur, provided-interface=IF_BMC_Sperrung_Uebertemperatur
      SP_IF_BMC_Sperrung_Unterspannung_XIX_BMC_HV: nonqueued-sender-com-spec=DE_BMC_Sperrung_Unterspannung, provided-interface=IF_BMC_Sperrung_Unterspannung
      SP_IF_BMC_Status_DCLS_XIX_BMC_HV: nonqueued-sender-com-spec=DE_BMC_Status_DCLS, provided-interface=IF_BMC_Status_DCLS
      SP_IF_BMC_Status_HV_Spannungssensorik_XIX_BMC_HV: nonqueued-sender-com-spec=DE_BMC_Status_HV_Spannungssensorik, provided-interface=IF_BMC_Status_HV_Spannungssensorik
      SP_IF_BMC_Status_Spgfreiheit_XIX_BMC_HV: nonqueued-sender-com-spec=DE_BMC_Status_Spgfreiheit, provided-interface=IF_BMC_Status_Spgfreiheit
      SP_IF_BMC_Status_Trennelemente_XIX_BMC_HV: nonqueued-sender-com-spec=DE_BMC_Status_Trennelemente, provided-interface=IF_BMC_Status_Trennelemente
      SP_IF_BMC_Strom_02_XIX_BMC_HV: nonqueued-sender-com-spec=DE_BMC_Strom_02, provided-interface=IF_BMC_Strom_02
      SP_IF_BMC_Strom_Messzeit_XIX_BMC_HV: nonqueued-sender-com-spec=DE_BMC_Strom_Messzeit, provided-interface=IF_BMC_Strom_Messzeit
      SP_IF_BMC_Strom_XIX_BMC_HV: nonqueued-sender-com-spec=DE_BMC_Strom, provided-interface=IF_BMC_Strom
      SP_IF_BMC_TechnischerSOC_XIX_BMC_HV: nonqueued-sender-com-spec=DE_BMC_TechnischerSOC, provided-interface=IF_BMC_TechnischerSOC
      SP_IF_BMC_Temperatur_hoechste_XIX_BMC_HV: nonqueued-sender-com-spec=DE_BMC_Temperatur_hoechste, provided-interface=IF_BMC_Temperatur_hoechste
      SP_IF_BMC_Temperatur_niedrigste_XIX_BMC_HV: nonqueued-sender-com-spec=DE_BMC_Temperatur_niedrigste, provided-interface=IF_BMC_Temperatur_niedrigste
      SP_IF_BMC_Temperatur_XIX_BMC_HV: nonqueued-sender-com-spec=DE_BMC_Temperatur, provided-interface=IF_BMC_Temperatur
      SP_IF_BMC_ThermAuslastung_XIX_BMC_HV: nonqueued-sender-com-spec=DE_BMC_ThermAuslastung, provided-interface=IF_BMC_ThermAuslastung
      SP_IF_BMC_ThermSpreizung_XIX_BMC_HV: nonqueued-sender-com-spec=DE_BMC_ThermSpreizung, provided-interface=IF_BMC_ThermSpreizung
      SP_IF_BMC_UBE_Indik_last_update_km_XIX_BMC_HV: nonqueued-sender-com-spec=DE_BMC_UBE_Indik_last_update_km, provided-interface=IF_BMC_UBE_Indik_last_update_km
      SP_IF_BMC_UBE_Indikator_XIX_BMC_HV: nonqueued-sender-com-spec=DE_BMC_UBE_Indikator, provided-interface=IF_BMC_UBE_Indikator
      SP_IF_BMC_Ueberspannungszaehler_CMC{01..04}_XIX_BMC_HV: nonqueued-sender-com-spec=DE_BMC_Ueberspannungszaehler_CMC{01..04}, provided-interface=IF_BMC_Ueberspannungszaehler_CMC{01..04}
      SP_IF_BMC_Uebertemperaturzaehler_CMC{01..04}_XIX_BMC_HV: nonqueued-sender-com-spec=DE_BMC_Uebertemperaturzaehler_CMC{01..04}, provided-interface=IF_BMC_Uebertemperaturzaehler_CMC{01..04}
      SP_IF_BMC_UI1_Spannung1_Schalt_Anf_XIX_BMC_HV: nonqueued-sender-com-spec=DE_BMC_UI1_Spannung1_Schalt_Anf, provided-interface=IF_BMC_UI1_Spannung1_Schalt_Anf
      SP_IF_BMC_UI1_Spannung2_Schalt_Anf_XIX_BMC_HV: nonqueued-sender-com-spec=DE_BMC_UI1_Spannung2_Schalt_Anf, provided-interface=IF_BMC_UI1_Spannung2_Schalt_Anf
      SP_IF_BMC_UI2_Spannung1_Schalt_Anf_XIX_BMC_HV: nonqueued-sender-com-spec=DE_BMC_UI2_Spannung1_Schalt_Anf, provided-interface=IF_BMC_UI2_Spannung1_Schalt_Anf
      SP_IF_BMC_UI2_Spannung2_Schalt_Anf_XIX_BMC_HV: nonqueued-sender-com-spec=DE_BMC_UI2_Spannung2_Schalt_Anf, provided-interface=IF_BMC_UI2_Spannung2_Schalt_Anf
      SP_IF_BMC_Unterboden_Warnung_XIX_BMC_HV: nonqueued-sender-com-spec=DE_BMC_Unterboden_Warnung, provided-interface=IF_BMC_Unterboden_Warnung
      SP_IF_BMC_Unterspannungszaehler_CMC{01..04}_XIX_BMC_HV: nonqueued-sender-com-spec=DE_BMC_Unterspannungszaehler_CMC{01..04}, provided-interface=IF_BMC_Unterspannungszaehler_CMC{01..04}
      SP_IF_BMC_Verbauinfo_ACSchuetz_XIX_BMC_HV: nonqueued-sender-com-spec=DE_BMC_Verbauinfo_ACSchuetz, provided-interface=IF_BMC_Verbauinfo_ACSchuetz
      SP_IF_BMC_Verbauinfo_Bank_XIX_BMC_HV: nonqueued-sender-com-spec=DE_BMC_Verbauinfo_Bank, provided-interface=IF_BMC_Verbauinfo_Bank
      SP_IF_BMC_Verbrauch_Ueberlauf_XIX_BMC_HV: nonqueued-sender-com-spec=DE_BMC_Verbrauch_Ueberlauf, provided-interface=IF_BMC_Verbrauch_Ueberlauf
      SP_IF_BMC_Verbrauch_XIX_BMC_HV: nonqueued-sender-com-spec=DE_BMC_Verbrauch, provided-interface=IF_BMC_Verbrauch
      SP_IF_BMC_VerlustEnergie_XIX_BMC_HV: nonqueued-sender-com-spec=DE_BMC_VerlustEnergie, provided-interface=IF_BMC_VerlustEnergie
      SP_IF_BMC_Vorlade_Zielspannung_XIX_BMC_HV: nonqueued-sender-com-spec=DE_BMC_Vorlade_Zielspannung, provided-interface=IF_BMC_Vorlade_Zielspannung
      SP_IF_BMC_VorlaufTemperatur_XIX_BMC_HV: nonqueued-sender-com-spec=DE_BMC_VorlaufTemperatur, provided-interface=IF_BMC_VorlaufTemperatur
      SP_IF_BMC_ZellTemp_virtuell_max_XIX_BMC_HV: nonqueued-sender-com-spec=DE_BMC_ZellTemp_virtuell_max, provided-interface=IF_BMC_ZellTemp_virtuell_max
      SP_IF_BMC_ZellTemp_virtuell_min_XIX_BMC_HV: nonqueued-sender-com-spec=DE_BMC_ZellTemp_virtuell_min, provided-interface=IF_BMC_ZellTemp_virtuell_min
      SP_IF_DS_Hybrid_01_ConfDTCChanged_XIX_BMC_HV: nonqueued-sender-com-spec=DE_DS_Hybrid_01_ConfDTCChanged, provided-interface=IF_DS_Hybrid_01_ConfDTCChanged
      SP_IF_DS_Hybrid_01_DiagAdr_XIX_BMC_HV: nonqueued-sender-com-spec=DE_DS_Hybrid_01_DiagAdr, provided-interface=IF_DS_Hybrid_01_DiagAdr
      SP_IF_DS_Hybrid_01_IdentValid_XIX_BMC_HV: nonqueued-sender-com-spec=DE_DS_Hybrid_01_IdentValid, provided-interface=IF_DS_Hybrid_01_IdentValid
      SP_IF_DS_Hybrid_01_Lokalaktiv_XIX_BMC_HV: nonqueued-sender-com-spec=DE_DS_Hybrid_01_Lokalaktiv, provided-interface=IF_DS_Hybrid_01_Lokalaktiv
      SP_IF_DS_Hybrid_01_MemSel10Changed_XIX_BMC_HV: nonqueued-sender-com-spec=DE_DS_Hybrid_01_MemSel10Changed, provided-interface=IF_DS_Hybrid_01_MemSel10Changed
      SP_IF_DS_Hybrid_01_MemSelChanged_XIX_BMC_HV: nonqueued-sender-com-spec=DE_DS_Hybrid_01_MemSelChanged, provided-interface=IF_DS_Hybrid_01_MemSelChanged
      SP_IF_DS_Hybrid_01_StMemChanged_XIX_BMC_HV: nonqueued-sender-com-spec=DE_DS_Hybrid_01_StMemChanged, provided-interface=IF_DS_Hybrid_01_StMemChanged
      SP_IF_DS_Hybrid_01_Subsystemaktiv_XIX_BMC_HV: nonqueued-sender-com-spec=DE_DS_Hybrid_01_Subsystemaktiv, provided-interface=IF_DS_Hybrid_01_Subsystemaktiv
      SP_IF_DS_Hybrid_01_TestFailedChanged_XIX_BMC_HV: nonqueued-sender-com-spec=DE_DS_Hybrid_01_TestFailedChanged, provided-interface=IF_DS_Hybrid_01_TestFailedChanged
      SP_IF_DS_Hybrid_01_WIRChanged_XIX_BMC_HV: nonqueued-sender-com-spec=DE_DS_Hybrid_01_WIRChanged, provided-interface=IF_DS_Hybrid_01_WIRChanged
      SP_IF_Hybrid_01_Indc_StChk_XIX_BMC_HV: nonqueued-sender-com-spec=DE_Hybrid_01_Indc_StChk, provided-interface=IF_Hybrid_01_Indc_StChk
      SP_IF_Hybrid_01_Indc_StFail_XIX_BMC_HV: nonqueued-sender-com-spec=DE_Hybrid_01_Indc_StFail, provided-interface=IF_Hybrid_01_Indc_StFail
      SP_IF_Hybrid_01_KD_Fehler_XIX_BMC_HV: nonqueued-sender-com-spec=DE_Hybrid_01_KD_Fehler, provided-interface=IF_Hybrid_01_KD_Fehler
      SP_IF_Hybrid_01_Nachlauftyp_XIX_BMC_HV: nonqueued-sender-com-spec=DE_Hybrid_01_Nachlauftyp, provided-interface=IF_Hybrid_01_Nachlauftyp
      SP_IF_Hybrid_01_OBD_Lampe_Anf_XIX_BMC_HV: nonqueued-sender-com-spec=DE_Hybrid_01_OBD_Lampe_Anf, provided-interface=IF_Hybrid_01_OBD_Lampe_Anf
      SP_IF_Hybrid_01_SNI_10_XIX_BMC_HV: nonqueued-sender-com-spec=DE_Hybrid_01_SNI_10, provided-interface=IF_Hybrid_01_SNI_10
      SP_IF_KN_Hybrid_01_DiagPfad_V12_XIX_BMC_HV: nonqueued-sender-com-spec=DE_KN_Hybrid_01_DiagPfad_V12, provided-interface=IF_KN_Hybrid_01_DiagPfad_V12
      SP_IF_KS_Hybrid_01_ChK_IKACtr_XIX_BMC_HV: nonqueued-sender-com-spec=DE_KS_Hybrid_01_ChK_IKACtr, provided-interface=IF_KS_Hybrid_01_ChK_IKACtr
      SP_IF_KS_Hybrid_01_ChK_SID_XIX_BMC_HV: nonqueued-sender-com-spec=DE_KS_Hybrid_01_ChK_SID, provided-interface=IF_KS_Hybrid_01_ChK_SID
      SP_IF_KS_Hybrid_01_ChK_XIX_BMC_HV: nonqueued-sender-com-spec=DE_KS_Hybrid_01_ChK, provided-interface=IF_KS_Hybrid_01_ChK
      SP_IF_KS_Hybrid_01_ReK_IKACtr_XIX_BMC_HV: nonqueued-sender-com-spec=DE_KS_Hybrid_01_ReK_IKACtr, provided-interface=IF_KS_Hybrid_01_ReK_IKACtr
      SP_IF_KS_Hybrid_01_ReK_SID_XIX_BMC_HV: nonqueued-sender-com-spec=DE_KS_Hybrid_01_ReK_SID, provided-interface=IF_KS_Hybrid_01_ReK_SID
      SP_IF_KS_Hybrid_01_ReK_XIX_BMC_HV: nonqueued-sender-com-spec=DE_KS_Hybrid_01_ReK, provided-interface=IF_KS_Hybrid_01_ReK
      SP_IF_KS_Hybrid_01_Req_ErrCtr_XIX_BMC_HV: nonqueued-sender-com-spec=DE_KS_Hybrid_01_Req_ErrCtr, provided-interface=IF_KS_Hybrid_01_Req_ErrCtr
      SP_IF_KS_Hybrid_01_Req_IKA_Retry_XIX_BMC_HV: nonqueued-sender-com-spec=DE_KS_Hybrid_01_Req_IKA_Retry, provided-interface=IF_KS_Hybrid_01_Req_IKA_Retry
      SP_IF_KS_Hybrid_01_Req_Prio_XIX_BMC_HV: nonqueued-sender-com-spec=DE_KS_Hybrid_01_Req_Prio, provided-interface=IF_KS_Hybrid_01_Req_Prio
      SP_IF_KS_Hybrid_01_Req_SID_XIX_BMC_HV: nonqueued-sender-com-spec=DE_KS_Hybrid_01_Req_SID, provided-interface=IF_KS_Hybrid_01_Req_SID
      SP_IF_KS_Hybrid_01_Req_SWMaj_XIX_BMC_HV: nonqueued-sender-com-spec=DE_KS_Hybrid_01_Req_SWMaj, provided-interface=IF_KS_Hybrid_01_Req_SWMaj
      SP_IF_KS_Hybrid_01_Req_SWMin_XIX_BMC_HV: nonqueued-sender-com-spec=DE_KS_Hybrid_01_Req_SWMin, provided-interface=IF_KS_Hybrid_01_Req_SWMin
      SP_IF_KS_Hybrid_01_Req_SWPat_XIX_BMC_HV: nonqueued-sender-com-spec=DE_KS_Hybrid_01_Req_SWPat, provided-interface=IF_KS_Hybrid_01_Req_SWPat
      SP_IF_KS_Hybrid_01_Req_VKMS_Err_XIX_BMC_HV: nonqueued-sender-com-spec=DE_KS_Hybrid_01_Req_VKMS_Err, provided-interface=IF_KS_Hybrid_01_Req_VKMS_Err
      SP_IF_NM_Hybrid_01_CAB_V12_XIX_BMC_HV: nonqueued-sender-com-spec=DE_NM_Hybrid_01_CAB_V12, provided-interface=IF_NM_Hybrid_01_CAB_V12
      SP_IF_NM_Hybrid_01_CBV_AWB_XIX_BMC_HV: nonqueued-sender-com-spec=DE_NM_Hybrid_01_CBV_AWB, provided-interface=IF_NM_Hybrid_01_CBV_AWB
      SP_IF_NM_Hybrid_01_FCAB_XIX_BMC_HV: nonqueued-sender-com-spec=DE_NM_Hybrid_01_FCAB, provided-interface=IF_NM_Hybrid_01_FCAB
      SP_IF_NM_Hybrid_01_FCIB_XIX_BMC_HV: nonqueued-sender-com-spec=DE_NM_Hybrid_01_FCIB, provided-interface=IF_NM_Hybrid_01_FCIB
      SP_IF_NM_Hybrid_01_NM_State_XIX_BMC_HV: nonqueued-sender-com-spec=DE_NM_Hybrid_01_NM_State, provided-interface=IF_NM_Hybrid_01_NM_State
      SP_IF_NM_Hybrid_01_SNI_10_XIX_BMC_HV: nonqueued-sender-com-spec=DE_NM_Hybrid_01_SNI_10, provided-interface=IF_NM_Hybrid_01_SNI_10
      SP_IF_OBDProtocol_Hybrid_01_XIX_BMC_HV: nonqueued-sender-com-spec=DE_OBDProtocol_Hybrid_01, provided-interface=IF_OBDProtocol_Hybrid_01
      SP_IF_SOK_Zeit_Hybrid_01_Challenge_XIX_BMC_HV: nonqueued-sender-com-spec=DE_SOK_Zeit_Hybrid_01_Challenge, provided-interface=IF_SOK_Zeit_Hybrid_01_Challenge
    383 x require port:
      RP_IF_AB_Deaktivierung_HV_XIX_BMC_HV: nonqueued-receiver-com-spec=data-element=DE_AB_Deaktivierung_HV, required-interface=IF_AB_Deaktivierung_HV
      RP_IF_BJB_CALID_Index_{01..16}_XIX_BMC_HV: nonqueued-receiver-com-spec=data-element=DE_BJB_CALID_Index_{01..16}, required-interface=IF_BJB_CALID_Index_{01..16}
      RP_IF_BJB_CVN_Byte_{1..4}_XIX_BMC_HV: nonqueued-receiver-com-spec=data-element=DE_BJB_CVN_Byte_{1..4}, required-interface=IF_BJB_CVN_Byte_{1..4}
      RP_IF_BJB_CVN_VLD_XIX_BMC_HV: nonqueued-receiver-com-spec=data-element=DE_BJB_CVN_VLD, required-interface=IF_BJB_CVN_VLD
      RP_IF_BJB_ErrMem_State_XIX_BMC_HV: nonqueued-receiver-com-spec=data-element=DE_BJB_ErrMem_State, required-interface=IF_BJB_ErrMem_State
      RP_IF_CHA_ReqPrgBms_XIX_BMC_HV: nonqueued-receiver-com-spec=data-element=DE_CHA_ReqPrgBms, required-interface=IF_CHA_ReqPrgBms
      RP_IF_DC_IstLeistung_HV_XIX_BMC_HV: nonqueued-receiver-com-spec=data-element=DE_DC_IstLeistung_HV, required-interface=IF_DC_IstLeistung_HV
      RP_IF_DCDC_NV_CALID_Index_{01..16}_XIX_BMC_HV: nonqueued-receiver-com-spec=data-element=DE_DCDC_NV_CALID_Index_{01..16}, required-interface=IF_DCDC_NV_CALID_Index_{01..16}
      RP_IF_DCDC_NV_CVN_Byte_{1..4}_XIX_BMC_HV: nonqueued-receiver-com-spec=data-element=DE_DCDC_NV_CVN_Byte_{1..4}, required-interface=IF_DCDC_NV_CVN_Byte_{1..4}
      RP_IF_DCDC_NV_CVN_VLD_XIX_BMC_HV: nonqueued-receiver-com-spec=data-element=DE_DCDC_NV_CVN_VLD, required-interface=IF_DCDC_NV_CVN_VLD
      RP_IF_DCDC_NV_Komponentenfehler_{01..39}_XIX_BMC_HV: nonqueued-receiver-com-spec=data-element=DE_DCDC_NV_Komponentenfehler_{01..39}, required-interface=IF_DCDC_NV_Komponentenfehler_{01..39}
      RP_IF_DCDC_NV_Komponentenfehler_3_{10..16}_XIX_BMC_HV: nonqueued-receiver-com-spec=data-element=DE_DCDC_NV_Komponentenfehler_3_{10..16}, required-interface=IF_DCDC_NV_Komponentenfehler_3_{10..16}
      RP_IF_DCDC_NV_Komponentenfehler_3_{1..9}_XIX_BMC_HV: nonqueued-receiver-com-spec=data-element=DE_DCDC_NV_Komponentenfehler_3_{1..9}, required-interface=IF_DCDC_NV_Komponentenfehler_3_{1..9}
      RP_IF_DCDC_NV_Komponentenfehler_{40..80}_XIX_BMC_HV: nonqueued-receiver-com-spec=data-element=DE_DCDC_NV_Komponentenfehler_{40..80}, required-interface=IF_DCDC_NV_Komponentenfehler_{40..80}
      RP_IF_DCDC_NV_Komponentenfehler_VLD_XIX_BMC_HV: nonqueued-receiver-com-spec=data-element=DE_DCDC_NV_Komponentenfehler_VLD, required-interface=IF_DCDC_NV_Komponentenfehler_VLD
      RP_IF_DW_Kilometerstand_XIX_BMC_HV: nonqueued-receiver-com-spec=data-element=DE_DW_Kilometerstand, required-interface=IF_DW_Kilometerstand
      RP_IF_EKK_HVK_EoHVL_Status_XIX_BMC_HV: nonqueued-receiver-com-spec=data-element=DE_EKK_HVK_EoHVL_Status, required-interface=IF_EKK_HVK_EoHVL_Status
      RP_IF_HVEM_BMC_CHA_Wunschleistung_02_XIX_BMC_HV: nonqueued-receiver-com-spec=data-element=DE_HVEM_BMC_CHA_Wunschleistung_02, required-interface=IF_HVEM_BMC_CHA_Wunschleistung_02
      RP_IF_HVEM_BMC_CHA_Wunschleistung_XIX_BMC_HV: nonqueued-receiver-com-spec=data-element=DE_HVEM_BMC_CHA_Wunschleistung, required-interface=IF_HVEM_BMC_CHA_Wunschleistung
      RP_IF_HVEM_MMTR_State_XIX_BMC_HV: nonqueued-receiver-com-spec=data-element=DE_HVEM_MMTR_State, required-interface=IF_HVEM_MMTR_State
      RP_IF_HVEM_SystemMinLeistungsgrenze_XIX_BMC_HV: nonqueued-receiver-com-spec=data-element=DE_HVEM_SystemMinLeistungsgrenze, required-interface=IF_HVEM_SystemMinLeistungsgrenze
      RP_IF_HVLE_IstSpannung_HV_XIX_BMC_HV: nonqueued-receiver-com-spec=data-element=DE_HVLE_IstSpannung_HV, required-interface=IF_HVLE_IstSpannung_HV
      RP_IF_HVLE_OBG_IstModus_XIX_BMC_HV: nonqueued-receiver-com-spec=data-element=DE_HVLE_OBG_IstModus, required-interface=IF_HVLE_OBG_IstModus
      RP_IF_HVLM_BCAM_Aktiv_XIX_BMC_HV: nonqueued-receiver-com-spec=data-element=DE_HVLM_BCAM_Aktiv, required-interface=IF_HVLM_BCAM_Aktiv
      RP_IF_HVLM_BidiLadeModus_XIX_BMC_HV: nonqueued-receiver-com-spec=data-element=DE_HVLM_BidiLadeModus, required-interface=IF_HVLM_BidiLadeModus
      RP_IF_KST_KL_15_XIX_BMC_HV: nonqueued-receiver-com-spec=data-element=DE_KST_KL_15, required-interface=IF_KST_KL_15
      RP_IF_MM_PropulsionSystemActive_XIX_BMC_HV: nonqueued-receiver-com-spec=data-element=DE_MM_PropulsionSystemActive, required-interface=IF_MM_PropulsionSystemActive
      RP_IF_NM_AWC_FCAB_XIX_BMC_HV: nonqueued-receiver-com-spec=data-element=DE_NM_AWC_FCAB, required-interface=IF_NM_AWC_FCAB
      RP_IF_NM_Gateway_FCAB_XIX_BMC_HV: nonqueued-receiver-com-spec=data-element=DE_NM_Gateway_FCAB, required-interface=IF_NM_Gateway_FCAB
      RP_IF_NM_HVZB_FCAB_XIX_BMC_HV: nonqueued-receiver-com-spec=data-element=DE_NM_HVZB_FCAB, required-interface=IF_NM_HVZB_FCAB
      RP_IF_NM_Ladegeraet_FCAB_XIX_BMC_HV: nonqueued-receiver-com-spec=data-element=DE_NM_Ladegeraet_FCAB, required-interface=IF_NM_Ladegeraet_FCAB
      RP_IF_NM_SACID_1_FCAB_XIX_BMC_HV: nonqueued-receiver-com-spec=data-element=DE_NM_SACID_1_FCAB, required-interface=IF_NM_SACID_1_FCAB
      RP_IF_NM_SACID_2_FCAB_XIX_BMC_HV: nonqueued-receiver-com-spec=data-element=DE_NM_SACID_2_FCAB, required-interface=IF_NM_SACID_2_FCAB
      RP_IF_NVEM_Abschaltstufe_XIX_BMC_HV: nonqueued-receiver-com-spec=data-element=DE_NVEM_Abschaltstufe, required-interface=IF_NVEM_Abschaltstufe
      RP_IF_OBD_Abs_Pedal_Pos_XIX_BMC_HV: nonqueued-receiver-com-spec=data-element=DE_OBD_Abs_Pedal_Pos, required-interface=IF_OBD_Abs_Pedal_Pos
      RP_IF_OBD_Aussen_Temp_gef_XIX_BMC_HV: nonqueued-receiver-com-spec=data-element=DE_OBD_Aussen_Temp_gef, required-interface=IF_OBD_Aussen_Temp_gef
      RP_IF_OBD_Barometric_Pressure_XIX_BMC_HV: nonqueued-receiver-com-spec=data-element=DE_OBD_Barometric_Pressure, required-interface=IF_OBD_Barometric_Pressure
      RP_IF_OBD_Calc_Load_Val_XIX_BMC_HV: nonqueued-receiver-com-spec=data-element=DE_OBD_Calc_Load_Val, required-interface=IF_OBD_Calc_Load_Val
      RP_IF_OBD_ClearMem_Inhibit_XIX_BMC_HV: nonqueued-receiver-com-spec=data-element=DE_OBD_ClearMem_Inhibit, required-interface=IF_OBD_ClearMem_Inhibit
      RP_IF_OBD_Driving_Cycle_XIX_BMC_HV: nonqueued-receiver-com-spec=data-element=DE_OBD_Driving_Cycle, required-interface=IF_OBD_Driving_Cycle
      RP_IF_OBD_Eng_Cool_Temp_XIX_BMC_HV: nonqueued-receiver-com-spec=data-element=DE_OBD_Eng_Cool_Temp, required-interface=IF_OBD_Eng_Cool_Temp
      RP_IF_OBD_Engine_RPM_XIX_BMC_HV: nonqueued-receiver-com-spec=data-element=DE_OBD_Engine_RPM, required-interface=IF_OBD_Engine_RPM
      RP_IF_OBD_Kaltstart_Denominator_XIX_BMC_HV: nonqueued-receiver-com-spec=data-element=DE_OBD_Kaltstart_Denominator, required-interface=IF_OBD_Kaltstart_Denominator
      RP_IF_OBD_Minimum_Trip_XIX_BMC_HV: nonqueued-receiver-com-spec=data-element=DE_OBD_Minimum_Trip, required-interface=IF_OBD_Minimum_Trip
      RP_IF_OBD_Normed_Trip_XIX_BMC_HV: nonqueued-receiver-com-spec=data-element=DE_OBD_Normed_Trip, required-interface=IF_OBD_Normed_Trip
      RP_IF_OBD_NumDcyMilOnReq_XIX_BMC_HV: nonqueued-receiver-com-spec=data-element=DE_OBD_NumDcyMilOnReq, required-interface=IF_OBD_NumDcyMilOnReq
      RP_IF_OBD_QBit_Aussen_Temp_XIX_BMC_HV: nonqueued-receiver-com-spec=data-element=DE_OBD_QBit_Aussen_Temp, required-interface=IF_OBD_QBit_Aussen_Temp
      RP_IF_OBD_Sperrung_IUMPR_XIX_BMC_HV: nonqueued-receiver-com-spec=data-element=DE_OBD_Sperrung_IUMPR, required-interface=IF_OBD_Sperrung_IUMPR
      RP_IF_OBD_Sperrung_Kaltstart_Denom_XIX_BMC_HV: nonqueued-receiver-com-spec=data-element=DE_OBD_Sperrung_Kaltstart_Denom, required-interface=IF_OBD_Sperrung_Kaltstart_Denom
      RP_IF_OBD_Typ_XIX_BMC_HV: nonqueued-receiver-com-spec=data-element=DE_OBD_Typ, required-interface=IF_OBD_Typ
      RP_IF_OBD_Warm_Up_Cycle_XIX_BMC_HV: nonqueued-receiver-com-spec=data-element=DE_OBD_Warm_Up_Cycle, required-interface=IF_OBD_Warm_Up_Cycle
      RP_IF_OBDProtocol_req_XIX_BMC_HV: nonqueued-receiver-com-spec=data-element=DE_OBDProtocol_req, required-interface=IF_OBDProtocol_req
      RP_IF_ORU_Status_XIX_BMC_HV: nonqueued-receiver-com-spec=data-element=DE_ORU_Status, required-interface=IF_ORU_Status
      RP_IF_OTP_Aussen_Temp_OBD_XIX_BMC_HV: nonqueued-receiver-com-spec=data-element=DE_OTP_Aussen_Temp_OBD, required-interface=IF_OTP_Aussen_Temp_OBD
      RP_IF_OTP_Aussen_Temp_ungef_XIX_BMC_HV: nonqueued-receiver-com-spec=data-element=DE_OTP_Aussen_Temp_ungef, required-interface=IF_OTP_Aussen_Temp_ungef
      RP_IF_PCM_BMC_VTD_Freeze_Req_XIX_BMC_HV: nonqueued-receiver-com-spec=data-element=DE_PCM_BMC_VTD_Freeze_Req, required-interface=IF_PCM_BMC_VTD_Freeze_Req
      RP_IF_PCM_BMC_VTD_LifeTimeReset_Req_XIX_BMC_HV: nonqueued-receiver-com-spec=data-element=DE_PCM_BMC_VTD_LifeTimeReset_Req, required-interface=IF_PCM_BMC_VTD_LifeTimeReset_Req
      RP_IF_PCM_BMC_VTD_LifeTimeReset_Resp_XIX_BMC_HV: nonqueued-receiver-com-spec=data-element=DE_PCM_BMC_VTD_LifeTimeReset_Resp, required-interface=IF_PCM_BMC_VTD_LifeTimeReset_Resp
      RP_IF_PCM_BMC_VTD_RecentReset_Req_XIX_BMC_HV: nonqueued-receiver-com-spec=data-element=DE_PCM_BMC_VTD_RecentReset_Req, required-interface=IF_PCM_BMC_VTD_RecentReset_Req
      RP_IF_SG_BJB_{10..13}_XIX_BMC_HV: nonqueued-receiver-com-spec=data-element=DE_SG_BJB_{10..13}, required-interface=IF_SG_BJB_{10..13}
      RP_IF_SG_HVK_03_XIX_BMC_HV: nonqueued-receiver-com-spec=data-element=DE_SG_HVK_03, required-interface=IF_SG_HVK_03
      RP_IF_SG_HVLM_14_XIX_BMC_HV: nonqueued-receiver-com-spec=data-element=DE_SG_HVLM_14, required-interface=IF_SG_HVLM_14
      RP_IF_SG_KS_Hybrid_01_Challenge_M_XIX_BMC_HV: nonqueued-receiver-com-spec=data-element=DE_SG_KS_Hybrid_01_Challenge_M, required-interface=IF_SG_KS_Hybrid_01_Challenge_M
      RP_IF_SG_KS_Hybrid_01_Response_M_XIX_BMC_HV: nonqueued-receiver-com-spec=data-element=DE_SG_KS_Hybrid_01_Response_M, required-interface=IF_SG_KS_Hybrid_01_Response_M
      RP_IF_SG_ORU_Control_A_01_XIX_BMC_HV: nonqueued-receiver-com-spec=data-element=DE_SG_ORU_Control_A_01, required-interface=IF_SG_ORU_Control_A_01
      RP_IF_SG_ORU_Control_D_01_XIX_BMC_HV: nonqueued-receiver-com-spec=data-element=DE_SG_ORU_Control_D_01, required-interface=IF_SG_ORU_Control_D_01
      RP_IF_SG_OTAMC_D_01_XIX_BMC_HV: nonqueued-receiver-com-spec=data-element=DE_SG_OTAMC_D_01, required-interface=IF_SG_OTAMC_D_01
      RP_IF_SG_UI1_01_XIX_BMC_HV: nonqueued-receiver-com-spec=data-element=DE_SG_UI1_01, required-interface=IF_SG_UI1_01
      RP_IF_SG_UI1_02_XIX_BMC_HV: nonqueued-receiver-com-spec=data-element=DE_SG_UI1_02, required-interface=IF_SG_UI1_02
      RP_IF_SG_UI2_{01..03}_XIX_BMC_HV: nonqueued-receiver-com-spec=data-element=DE_SG_UI2_{01..03}, required-interface=IF_SG_UI2_{01..03}
      RP_IF_SI_NWDF_30_XIX_BMC_HV: nonqueued-receiver-com-spec=data-element=DE_SI_NWDF_30, required-interface=IF_SI_NWDF_30
      RP_IF_SI_NWDF_XIX_BMC_HV: nonqueued-receiver-com-spec=data-element=DE_SI_NWDF, required-interface=IF_SI_NWDF
      RP_IF_SI_P_Mode_gueltig_XIX_BMC_HV: nonqueued-receiver-com-spec=data-element=DE_SI_P_Mode_gueltig, required-interface=IF_SI_P_Mode_gueltig
      RP_IF_SI_P_Mode_XIX_BMC_HV: nonqueued-receiver-com-spec=data-element=DE_SI_P_Mode, required-interface=IF_SI_P_Mode
      RP_IF_SI_T_Mode_XIX_BMC_HV: nonqueued-receiver-com-spec=data-element=DE_SI_T_Mode, required-interface=IF_SI_T_Mode
      RP_IF_SOK_ungeschuetzte_Zeit_XIX_BMC_HV: nonqueued-receiver-com-spec=data-element=DE_SOK_ungeschuetzte_Zeit, required-interface=IF_SOK_ungeschuetzte_Zeit
      RP_IF_SOK_Zeit_Hybrid_01_Zeit_XIX_BMC_HV: nonqueued-receiver-com-spec=data-element=DE_SOK_Zeit_Hybrid_01_Zeit, required-interface=IF_SOK_Zeit_Hybrid_01_Zeit
      RP_IF_TME_Batt_Kond_Verf_XIX_BMC_HV: nonqueued-receiver-com-spec=data-element=DE_TME_Batt_Kond_Verf, required-interface=IF_TME_Batt_Kond_Verf
      RP_IF_TME_Therm_IstLeistung_HVBatterie_XIX_BMC_HV: nonqueued-receiver-com-spec=data-element=DE_TME_Therm_IstLeistung_HVBatterie, required-interface=IF_TME_Therm_IstLeistung_HVBatterie
      RP_IF_UH_Jahr_XIX_BMC_HV: nonqueued-receiver-com-spec=data-element=DE_UH_Jahr, required-interface=IF_UH_Jahr
      RP_IF_UH_Minute_XIX_BMC_HV: nonqueued-receiver-com-spec=data-element=DE_UH_Minute, required-interface=IF_UH_Minute
      RP_IF_UH_Monat_XIX_BMC_HV: nonqueued-receiver-com-spec=data-element=DE_UH_Monat, required-interface=IF_UH_Monat
      RP_IF_UH_Sekunde_XIX_BMC_HV: nonqueued-receiver-com-spec=data-element=DE_UH_Sekunde, required-interface=IF_UH_Sekunde
      RP_IF_UH_Stunde_XIX_BMC_HV: nonqueued-receiver-com-spec=data-element=DE_UH_Stunde, required-interface=IF_UH_Stunde
      RP_IF_UH_Tag_XIX_BMC_HV: nonqueued-receiver-com-spec=data-element=DE_UH_Tag, required-interface=IF_UH_Tag
      RP_IF_UI1_Iso_Neg_XIX_BMC_HV: nonqueued-receiver-com-spec=data-element=DE_UI1_Iso_Neg, required-interface=IF_UI1_Iso_Neg
      RP_IF_UI1_Iso_Pos_XIX_BMC_HV: nonqueued-receiver-com-spec=data-element=DE_UI1_Iso_Pos, required-interface=IF_UI1_Iso_Pos
      RP_IF_UI1_Iso_Status_XIX_BMC_HV: nonqueued-receiver-com-spec=data-element=DE_UI1_Iso_Status, required-interface=IF_UI1_Iso_Status
      RP_IF_UI1_KompFehlerModus2_{01..26}_XIX_BMC_HV: nonqueued-receiver-com-spec=data-element=DE_UI1_KompFehlerModus2_{01..26}, required-interface=IF_UI1_KompFehlerModus2_{01..26}
      RP_IF_UI1_KompFehlerModus4_{01..16}_XIX_BMC_HV: nonqueued-receiver-com-spec=data-element=DE_UI1_KompFehlerModus4_{01..16}, required-interface=IF_UI1_KompFehlerModus4_{01..16}
      RP_IF_UI1_Spannung{4..6}_XIX_BMC_HV: nonqueued-receiver-com-spec=data-element=DE_UI1_Spannung{4..6}, required-interface=IF_UI1_Spannung{4..6}
      RP_IF_UI1_Status_XIX_BMC_HV: nonqueued-receiver-com-spec=data-element=DE_UI1_Status, required-interface=IF_UI1_Status
      RP_IF_UI1_Stromintegral_Entladen_XIX_BMC_HV: nonqueued-receiver-com-spec=data-element=DE_UI1_Stromintegral_Entladen, required-interface=IF_UI1_Stromintegral_Entladen
      RP_IF_UI1_Stromintegral_Laden_XIX_BMC_HV: nonqueued-receiver-com-spec=data-element=DE_UI1_Stromintegral_Laden, required-interface=IF_UI1_Stromintegral_Laden
      RP_IF_UI1_Temperatur_1_XIX_BMC_HV: nonqueued-receiver-com-spec=data-element=DE_UI1_Temperatur_1, required-interface=IF_UI1_Temperatur_1
      RP_IF_UI1_Temperatur_2_XIX_BMC_HV: nonqueued-receiver-com-spec=data-element=DE_UI1_Temperatur_2, required-interface=IF_UI1_Temperatur_2
      RP_IF_UI2_KompFehlerModus2_{01..26}_XIX_BMC_HV: nonqueued-receiver-com-spec=data-element=DE_UI2_KompFehlerModus2_{01..26}, required-interface=IF_UI2_KompFehlerModus2_{01..26}
      RP_IF_UI2_KompFehlerModus4_{01..16}_XIX_BMC_HV: nonqueued-receiver-com-spec=data-element=DE_UI2_KompFehlerModus4_{01..16}, required-interface=IF_UI2_KompFehlerModus4_{01..16}
      RP_IF_UI2_Status_XIX_BMC_HV: nonqueued-receiver-com-spec=data-element=DE_UI2_Status, required-interface=IF_UI2_Status
      RP_IF_UI2_Stromintegral_Entladen_XIX_BMC_HV: nonqueued-receiver-com-spec=data-element=DE_UI2_Stromintegral_Entladen, required-interface=IF_UI2_Stromintegral_Entladen
      RP_IF_UI2_Stromintegral_Laden_XIX_BMC_HV: nonqueued-receiver-com-spec=data-element=DE_UI2_Stromintegral_Laden, required-interface=IF_UI2_Stromintegral_Laden
      RP_IF_UI2_Temperatur_1_XIX_BMC_HV: nonqueued-receiver-com-spec=data-element=DE_UI2_Temperatur_1, required-interface=IF_UI2_Temperatur_1
      RP_IF_UI2_Temperatur_2_XIX_BMC_HV: nonqueued-receiver-com-spec=data-element=DE_UI2_Temperatur_2, required-interface=IF_UI2_Temperatur_2
      RP_IF_UI2Sens01_CALID_Index_{01..16}_XIX_BMC_HV: nonqueued-receiver-com-spec=data-element=DE_UI2Sens01_CALID_Index_{01..16}, required-interface=IF_UI2Sens01_CALID_Index_{01..16}
      RP_IF_UI2Sens01_CVN_Byte_{1..4}_XIX_BMC_HV: nonqueued-receiver-com-spec=data-element=DE_UI2Sens01_CVN_Byte_{1..4}, required-interface=IF_UI2Sens01_CVN_Byte_{1..4}
      RP_IF_UI2Sens01_CVN_VLD_XIX_BMC_HV: nonqueued-receiver-com-spec=data-element=DE_UI2Sens01_CVN_VLD, required-interface=IF_UI2Sens01_CVN_VLD
      RP_IF_UI2Sens01_ErrMem_State_XIX_BMC_HV: nonqueued-receiver-com-spec=data-element=DE_UI2Sens01_ErrMem_State, required-interface=IF_UI2Sens01_ErrMem_State
      RP_IF_UI2Sens02_CALID_Index_{01..16}_XIX_BMC_HV: nonqueued-receiver-com-spec=data-element=DE_UI2Sens02_CALID_Index_{01..16}, required-interface=IF_UI2Sens02_CALID_Index_{01..16}
      RP_IF_UI2Sens02_CVN_Byte_{1..4}_XIX_BMC_HV: nonqueued-receiver-com-spec=data-element=DE_UI2Sens02_CVN_Byte_{1..4}, required-interface=IF_UI2Sens02_CVN_Byte_{1..4}
      RP_IF_UI2Sens02_CVN_VLD_XIX_BMC_HV: nonqueued-receiver-com-spec=data-element=DE_UI2Sens02_CVN_VLD, required-interface=IF_UI2Sens02_CVN_VLD
      RP_IF_UI2Sens02_ErrMem_State_XIX_BMC_HV: nonqueued-receiver-com-spec=data-element=DE_UI2Sens02_ErrMem_State, required-interface=IF_UI2Sens02_ErrMem_State
      RP_IF_VDSO_Vx3d_XIX_BMC_HV: nonqueued-receiver-com-spec=data-element=DE_VDSO_Vx3d, required-interface=IF_VDSO_Vx3d
      RP_IF_VIN_{10..17}_XIX_BMC_HV: nonqueued-receiver-com-spec=data-element=DE_VIN_{10..17}, required-interface=IF_VIN_{10..17}
      RP_IF_VIN_{1..9}_XIX_BMC_HV: nonqueued-receiver-com-spec=data-element=DE_VIN_{1..9}, required-interface=IF_VIN_{1..9}
      RP_IF_ZM_HV_Auszeit_HiRes_XIX_BMC_HV: nonqueued-receiver-com-spec=data-element=DE_ZM_HV_Auszeit_HiRes, required-interface=IF_ZM_HV_Auszeit_HiRes
      RP_IF_ZM_HV_Auszeit_Status_XIX_BMC_HV: nonqueued-receiver-com-spec=data-element=DE_ZM_HV_Auszeit_Status, required-interface=IF_ZM_HV_Auszeit_Status
      RP_IF_ZM_HV_Auszeit_XIX_BMC_HV: nonqueued-receiver-com-spec=data-element=DE_ZM_HV_Auszeit, required-interface=IF_ZM_HV_Auszeit
    9 x provide port:
      SP_IF_KN_Hybrid_01_ECUKnockOutTimer_XIX_Infrastructure_Hybrid_01_XIX_network_infrastructure_XIX_BMC_HV: provided-interface=IF_KN_Hybrid_01_ECUKnockOutTimer
      SP_IF_KN_Hybrid_01_BusKnockOut_XIX_Infrastructure_Hybrid_01_XIX_network_infrastructure_XIX_BMC_HV: provided-interface=IF_KN_Hybrid_01_BusKnockOut
      SP_IF_KN_Hybrid_01_ECUKnockOut_XIX_Infrastructure_Hybrid_01_XIX_network_infrastructure_XIX_BMC_HV: provided-interface=IF_KN_Hybrid_01_ECUKnockOut
      SP_IF_KN_Hybrid_01_BusKnockOutTimer_XIX_Infrastructure_Hybrid_01_XIX_network_infrastructure_XIX_BMC_HV: provided-interface=IF_KN_Hybrid_01_BusKnockOutTimer
      SP_IF_NM_Hybrid_01_NM_aktiv_Diag_XIX_Infrastructure_Hybrid_01_XIX_network_infrastructure_XIX_BMC_HV: provided-interface=IF_NM_Hybrid_01_NM_aktiv_Diag
      SP_IF_NM_Hybrid_01_UDS_CC_XIX_Infrastructure_Hybrid_01_XIX_network_infrastructure_XIX_BMC_HV: provided-interface=IF_NM_Hybrid_01_UDS_CC
      SP_IF_NM_Hybrid_01_CBV_CRI_XIX_Infrastructure_Hybrid_01_XIX_network_infrastructure_XIX_BMC_HV: provided-interface=IF_NM_Hybrid_01_CBV_CRI
      SP_IF_NM_Hybrid_01_NM_aktiv_Tmin_XIX_Infrastructure_Hybrid_01_XIX_network_infrastructure_XIX_BMC_HV: provided-interface=IF_NM_Hybrid_01_NM_aktiv_Tmin
      SP_IF_NM_Hybrid_01_NM_aktiv_KL15_XIX_Infrastructure_Hybrid_01_XIX_network_infrastructure_XIX_BMC_HV: provided-interface=IF_NM_Hybrid_01_NM_aktiv_KL15
    require port RP_IF_DEV_Hybrid_01_Req_00_FD_Data_XIX_Infrastructure_Hybrid_01_XIX_network_infrastructure_XIX_BMC_HV: required-interface=IF_DEV_Hybrid_01_Req_00_FD_Data
    6 x provide port:
      SP_IF_DEV_Hybrid_01_Resp_FF_FD_Data_XIX_Infrastructure_Hybrid_01_XIX_network_infrastructure_XIX_BMC_HV: provided-interface=IF_DEV_Hybrid_01_Resp_FF_FD_Data
      SP_IF_NM_Hybrid_01_Wakeup_V12_XIX_Infrastructure_Hybrid_01_XIX_network_infrastructure_XIX_BMC_HV: provided-interface=IF_NM_Hybrid_01_Wakeup_V12
      SP_IF_NM_aktiv_Konditionierungsbedarf_XIX_Infrastructure_Hybrid_01_XIX_network_infrastructure_XIX_BMC_HV: provided-interface=IF_NM_aktiv_Konditionierungsbedarf
      SP_IF_NM_Hybrid_01_Lokalaktiv_XIX_Infrastructure_Hybrid_01_XIX_network_infrastructure_XIX_BMC_HV: provided-interface=IF_NM_Hybrid_01_Lokalaktiv
      SP_IF_NM_Hybrid_01_Subsystemaktiv_XIX_Infrastructure_Hybrid_01_XIX_network_infrastructure_XIX_BMC_HV: provided-interface=IF_NM_Hybrid_01_Subsystemaktiv
      SP_IF_NM_aktiv_SubbusSteuerung_BMC_HV_XIX_Infrastructure_Hybrid_01_XIX_network_infrastructure_XIX_BMC_HV: provided-interface=IF_NM_aktiv_SubbusSteuerung_BMC_HV
    require port RP_IF_ISO_ALL_01_Req_Data_XIX_diagnosis_infrastructure_Hybrid_01_XIX_diagnosis_infrastructure_XIX_BMC_HV: required-interface=IF_ISO_ALL_01_Req_Data
    provide port SP_IF_ISO_ALL_01_Req_Data_XIX_diagnosis_infrastructure_Hybrid_01_XIX_diagnosis_infrastructure_XIX_BMC_HV: provided-interface=IF_ISO_ALL_01_Req_Data
    provide port SP_IF_Hybrid_01_KompSchutz_XIX_KS_BMC_HV_XIX_KSGen3_XIX_BMC_HV: provided-interface=IF_Hybrid_01_KompSchutz
    provide port SG_BMC_HV_13: nonqueued-sender-com-spec{data-element=SG_BMC_HV_13, init-value=fields=[BMC_HV_13_BZ:0, BMC_HV_13_CRC:0, BMC_Unterspannungszaehler_CMC01:510, BMC_Unterspannungszaehler_CMC02:510, BMC_Unterspannungszaehler_CMC03:510, BMC_Unterspannungszaehler_CMC04:510, SignalVoid_BMC_HV_13_0:0, SignalVoid_BMC_HV_13_1:0]}, provided-interface=SG_BMC_HV_13
    require port SG_UI1_01: nonqueued-receiver-com-spec{data-element=SG_UI1_01, init-value=fields=[SignalVoid_UI1_01_0:0, SignalVoid_UI1_01_1:0, SignalVoid_UI1_01_2:0, UI1_KL30_Spannung:254, UI1_Strom:1048574, UISensorIso_01_BZ:0, UISensorIso_01_CRC:0]}, required-interface=SG_UI1_01
    require port BJB_ErrMem_State: nonqueued-receiver-com-spec{data-element=BJB_ErrMem_State, init-value=2}, required-interface=BJB_ErrMem_State
    require port BJB_ErrMem_State_1: nonqueued-receiver-com-spec{data-element=BJB_ErrMem_State, init-value=2}, required-interface=BJB_ErrMem_State_1
    provide port SG_BMC_HV_12: nonqueued-sender-com-spec{data-element=SG_BMC_HV_12, init-value=fields=[BMC_HV_12_BZ:0, BMC_HV_12_CRC:0, BMC_Sperrung_Uebertemperatur:2, BMC_Ueberspannungszaehler_CMC03:510, BMC_Ueberspannungszaehler_CMC04:510, BMC_Uebertemperaturzaehler_CMC03:65534, BMC_Uebertemperaturzaehler_CMC04:65534]}, provided-interface=SG_BMC_HV_12
    require port AB_Deaktivierung_HV: nonqueued-receiver-com-spec{data-element=AB_Deaktivierung_HV, init-value=0}, required-interface=AB_Deaktivierung_HV
    11 x provide port:
      SG_BMC_HV_11: nonqueued-sender-com-spec{data-element=SG_BMC_HV_11, init-value=fields=[BMC_HV_11_BZ:0, BMC_HV_11_CRC:0, BMC_Sperrung_Ueberspannung:2, BMC_Ueberspannungszaehler_CMC01:510, BMC_Ueberspannungszaehler_CMC02:510, BMC_Uebertemperaturzaehler_CMC01:65534, BMC_Uebertemperaturzaehler_CMC02:65534]}, provided-interface=SG_BMC_HV_11
      SG_BMC_HV_14: nonqueued-sender-com-spec{data-element=SG_BMC_HV_11, init-value=fields=[BMC_HV_11_BZ:0, BMC_HV_11_CRC:0, BMC_Sperrung_Ueberspannung:2, BMC_Ueberspannungszaehler_CMC01:510, BMC_Ueberspannungszaehler_CMC02:510, BMC_Uebertemperaturzaehler_CMC01:65534, BMC_Uebertemperaturzaehler_CMC02:65534]}, provided-interface=SG_BMC_HV_14
      SG_BMC_HV_15: nonqueued-sender-com-spec{data-element=SG_BMC_HV_11, init-value=fields=[BMC_HV_11_BZ:0, BMC_HV_11_CRC:0, BMC_Sperrung_Ueberspannung:2, BMC_Ueberspannungszaehler_CMC01:510, BMC_Ueberspannungszaehler_CMC02:510, BMC_Uebertemperaturzaehler_CMC01:65534, BMC_Uebertemperaturzaehler_CMC02:65534]}, provided-interface=SG_BMC_HV_15
      SG_BMC_HV_10: nonqueued-sender-com-spec{data-element=SG_BMC_HV_10, init-value=fields=[BMC_Datenuebernahme_Anf:0, BMC_HV_10_BZ:0, BMC_HV_10_CRC:0, BMC_Lebensdauer_Trennelemente:131070, BMC_Sperrung_Unterspannung:2, BMC_Status_HV_Spannungssensorik:0, BMC_Status_Trennelemente:6, SignalVoid_BMC_HV_10_0:0, SignalVoid_BMC_HV_10_1:0, SignalVoid_BMC_HV_10_2:0, SignalVoid_BMC_HV_10_3:0]}, provided-interface=SG_BMC_HV_10
      SG_BMC_HV_16: nonqueued-sender-com-spec{data-element=SG_BMC_HV_11, init-value=fields=[BMC_HV_11_BZ:0, BMC_HV_11_CRC:0, BMC_Sperrung_Ueberspannung:2, BMC_Ueberspannungszaehler_CMC01:510, BMC_Ueberspannungszaehler_CMC02:510, BMC_Uebertemperaturzaehler_CMC01:65534, BMC_Uebertemperaturzaehler_CMC02:65534]}, provided-interface=SG_BMC_HV_16
      SG_BMC_HV_04: nonqueued-sender-com-spec{data-element=SG_BMC_HV_04, init-value=fields=[BMC_Dev_Freigabe:0, BMC_Flash_Freigabe:0, BMC_HV_04_BZ:0, BMC_HV_04_CRC:0, BMC_Iso_Mode_Anf:0, BMC_UI1_Spannung1_Schalt_Anf:0, BMC_UI1_Spannung2_Schalt_Anf:0, BMC_UI2_Spannung1_Schalt_Anf:0, BMC_UI2_Spannung2_Schalt_Anf:0, SignalVoid_BMC_HV_04_0:0, SignalVoid_BMC_HV_04_1:0, SignalVoid_BMC_HV_04_2:0, SignalVoid_BMC_HV_04_3:0, SignalVoid_BMC_HV_04_4:0, SignalVoid_BMC_HV_04_5:0]}, provided-interface=SG_BMC_HV_04
      SG_BMC_HV_01: nonqueued-sender-com-spec{data-element=SG_BMC_HV_01, init-value=fields=[BMC_Bankstatus:14, BMC_HV_01_BZ:0, BMC_HV_01_CRC:0, BMC_HVK_EoHVL_Status:0, BMC_HVK_Fehler_HVIL:3, BMC_HVK_Fehler_Intern:3, BMC_HVK_Fehler_SD:3, BMC_Modus:15, BMC_Spannung:16382, BMC_Spannung_Messzeit:254, BMC_Spannung_ZwischenKreis:16382, BMC_Spannung_ZwischenKreis_2:16382, BMC_Status_Spgfreiheit:0, BMC_Strom:65534, BMC_Strom_02:131070, BMC_Strom_Messzeit:254, SignalVoid_BMC_HV_01_0:0]}, provided-interface=SG_BMC_HV_01
      SG_BMC_HV_02: nonqueued-sender-com-spec{data-element=SG_BMC_HV_02, init-value=fields=[Anzeige_SOC:1022, BMC_AC_Laden:0, BMC_Bank_Notlauf_erlaubt:1, BMC_Bank_parallel_erlaubt:1, BMC_Bank_seriell_erlaubt:1, BMC_DC_Laden:0, BMC_Energie_Sockel_SoC:1022, BMC_Energieinhalt:65534, BMC_Fehler_Leistungsred:0, BMC_Fehler_Warnung:0, BMC_HV_02_BZ:0, BMC_HV_02_CRC:0, BMC_IstZellspannungMax:4094, BMC_IstZellspannungMin:4094, BMC_IWU_Status:0, BMC_IWU_Wert_neg:65534, BMC_IWU_Wert_pos:65534, BMC_Leerlaufspannung:1022, BMC_Max_Entladeleistung:8190, BMC_Max_Entladestrom:8190, BMC_Max_Ladeleistung:8190, BMC_Max_Ladestrom:8190, BMC_MinDyn_Entladespannung:1022, BMC_MinDyn_Ladespannung:1022, BMC_MMTR_Status:14, BMC_NutzbarerSOC:4094, BMC_PerfInd_Entladen:1022, BMC_PerfInd_Laden:1022, BMC_PredLeistung_StuetzungNV:4094, BMC_Spannung_DC_Ladesaeule:32766, BMC_Status_DCLS:0, BMC_TechnischerSOC:2046, BMC_Unterboden_Warnung:0, BMC_Verbauinfo_ACSchuetz:0, BMC_Verbauinfo_Bank:0, BMC_Vorlade_Zielspannung:1022, BMC_ZellTemp_virtuell_max:1022, BMC_ZellTemp_virtuell_min:1022, Hybrid_01_OBD_Lampe_Anf:0, SignalVoid_BMC_HV_02_0:0, SignalVoid_BMC_HV_02_1:0, SignalVoid_BMC_HV_02_2:0, SignalVoid_BMC_HV_02_3:0, SignalVoid_BMC_HV_02_4:0, SignalVoid_BMC_HV_02_5:0]}, provided-interface=SG_BMC_HV_02
      SG_KS_Hybrid_01_Challenge_K: nonqueued-sender-com-spec{data-element=SG_KS_Hybrid_01_Challenge_K, init-value=fields=[KS_Hybrid_01_ChK:8 x 0, KS_Hybrid_01_ChK_IKACtr:0, KS_Hybrid_01_ChK_SID:0]}, provided-interface=SG_KS_Hybrid_01_Challenge_K
      SG_KS_Hybrid_01_ReqFrame: nonqueued-sender-com-spec{data-element=SG_KS_Hybrid_01_ReqFrame, init-value=fields=[KS_Hybrid_01_Req_ErrCtr:0, KS_Hybrid_01_Req_IKA_Retry:0, KS_Hybrid_01_Req_Prio:0, KS_Hybrid_01_Req_SID:0, KS_Hybrid_01_Req_SWMaj:0, KS_Hybrid_01_Req_SWMin:0, KS_Hybrid_01_Req_SWPat:0, KS_Hybrid_01_Req_VKMS_Err:0]}, provided-interface=SG_KS_Hybrid_01_ReqFrame
      SG_KS_Hybrid_01_Response_K: nonqueued-sender-com-spec{data-element=SG_KS_Hybrid_01_Response_K, init-value=fields=[KS_Hybrid_01_ReK:8 x 0, KS_Hybrid_01_ReK_IKACtr:0, KS_Hybrid_01_ReK_SID:0]}, provided-interface=SG_KS_Hybrid_01_Response_K
    require port SG_BJB_11: nonqueued-receiver-com-spec{data-element=SG_BJB_11, init-value=fields=[BJB_11_BZ:0, BJB_11_CRC:0, BJB_Sperrung_Ueberspannung:2, BJB_Ueberspannungszaehler_CMC01:510, BJB_Ueberspannungszaehler_CMC02:510, BJB_Uebertemperaturzaehler_CMC01:65534, BJB_Uebertemperaturzaehler_CMC02:65534]}, required-interface=SG_BJB_11
    provide port SG_BMC_HV_18: nonqueued-sender-com-spec{data-element=SG_BMC_HV_10, init-value=fields=[BMC_Datenuebernahme_Anf:0, BMC_HV_10_BZ:0, BMC_HV_10_CRC:0, BMC_Lebensdauer_Trennelemente:131070, BMC_Sperrung_Unterspannung:2, BMC_Status_HV_Spannungssensorik:0, BMC_Status_Trennelemente:6, SignalVoid_BMC_HV_10_0:0, SignalVoid_BMC_HV_10_1:0, SignalVoid_BMC_HV_10_2:0, SignalVoid_BMC_HV_10_3:0]}, provided-interface=SG_BMC_HV_17
    6 x require port:
      SG_BJB_10: nonqueued-receiver-com-spec{data-element=SG_BJB_10, init-value=fields=[BJB_10_BZ:0, BJB_10_CRC:0, BJB_Lebensdauer_Trennelemente:131070, BJB_Sperrung_Unterspannung:2, BJB_Status_HV_Spannungssensorik:0, BJB_Status_Trennelemente:6, SignalVoid_BJB_10_0:0, SignalVoid_BJB_10_1:0, SignalVoid_BJB_10_2:0, SignalVoid_BJB_10_3:0]}, required-interface=SG_BJB_10
      SG_BJB_{12..14}: nonqueued-receiver-com-spec{data-element=SG_BJB_11, init-value=fields=[BJB_11_BZ:0, BJB_11_CRC:0, BJB_Sperrung_Ueberspannung:2, BJB_Ueberspannungszaehler_CMC01:510, BJB_Ueberspannungszaehler_CMC02:510, BJB_Uebertemperaturzaehler_CMC01:65534, BJB_Uebertemperaturzaehler_CMC02:65534]}, required-interface=SG_BJB_{12..14}
      SG_BJB_15: nonqueued-receiver-com-spec{data-element=SG_BJB_12, init-value=fields=[BJB_12_BZ:0, BJB_12_CRC:0, BJB_Sperrung_Uebertemperatur:2, BJB_Ueberspannungszaehler_CMC03:510, BJB_Ueberspannungszaehler_CMC04:510, BJB_Uebertemperaturzaehler_CMC03:65534, BJB_Uebertemperaturzaehler_CMC04:65534]}, required-interface=SG_BJB_15
      SG_BJB_16: nonqueued-receiver-com-spec{data-element=SG_BJB_13, init-value=fields=[BJB_13_BZ:0, BJB_13_CRC:0, BJB_Unterspannungszaehler_CMC01:510, BJB_Unterspannungszaehler_CMC02:510, BJB_Unterspannungszaehler_CMC03:510, BJB_Unterspannungszaehler_CMC04:510, SignalVoid_BJB_13_0:0, SignalVoid_BJB_13_1:0]}, required-interface=SG_BJB_16
    10 x provide port:
      SG_BMC_HV_5: nonqueued-sender-com-spec{data-element=SG_BMC_HV_04, init-value=fields=[BMC_Dev_Freigabe:0, BMC_Flash_Freigabe:0, BMC_HV_04_BZ:0, BMC_HV_04_CRC:0, BMC_Iso_Mode_Anf:0, BMC_UI1_Spannung1_Schalt_Anf:0, BMC_UI1_Spannung2_Schalt_Anf:0, BMC_UI2_Spannung1_Schalt_Anf:0, BMC_UI2_Spannung2_Schalt_Anf:0, SignalVoid_BMC_HV_04_0:0, SignalVoid_BMC_HV_04_1:0, SignalVoid_BMC_HV_04_2:0, SignalVoid_BMC_HV_04_3:0, SignalVoid_BMC_HV_04_4:0, SignalVoid_BMC_HV_04_5:0]}, provided-interface=SG_BMC_HV_5
      SG_BMC_HV_17: nonqueued-sender-com-spec{data-element=SG_BMC_HV_10, init-value=fields=[BMC_Datenuebernahme_Anf:0, BMC_HV_10_BZ:0, BMC_HV_10_CRC:0, BMC_Lebensdauer_Trennelemente:131070, BMC_Sperrung_Unterspannung:2, BMC_Status_HV_Spannungssensorik:0, BMC_Status_Trennelemente:6, SignalVoid_BMC_HV_10_0:0, SignalVoid_BMC_HV_10_1:0, SignalVoid_BMC_HV_10_2:0, SignalVoid_BMC_HV_10_3:0]}, provided-interface=SG_BMC_HV_18
      SG_BMC_HV_19: nonqueued-sender-com-spec{data-element=SG_BMC_HV_11, init-value=fields=[BMC_HV_11_BZ:0, BMC_HV_11_CRC:0, BMC_Sperrung_Ueberspannung:2, BMC_Ueberspannungszaehler_CMC01:510, BMC_Ueberspannungszaehler_CMC02:510, BMC_Uebertemperaturzaehler_CMC01:65534, BMC_Uebertemperaturzaehler_CMC02:65534]}, provided-interface=SG_BMC_HV_19
      SG_BMC_HV_20: nonqueued-sender-com-spec{data-element=SG_BMC_HV_12, init-value=fields=[BMC_HV_12_BZ:0, BMC_HV_12_CRC:0, BMC_Sperrung_Uebertemperatur:2, BMC_Ueberspannungszaehler_CMC03:510, BMC_Ueberspannungszaehler_CMC04:510, BMC_Uebertemperaturzaehler_CMC03:65534, BMC_Uebertemperaturzaehler_CMC04:65534]}, provided-interface=SG_BMC_HV_20
      SG_BMC_HV_21: nonqueued-sender-com-spec{data-element=SG_BMC_HV_13, init-value=fields=[BMC_HV_13_BZ:0, BMC_HV_13_CRC:0, BMC_Unterspannungszaehler_CMC01:510, BMC_Unterspannungszaehler_CMC02:510, BMC_Unterspannungszaehler_CMC03:510, BMC_Unterspannungszaehler_CMC04:510, SignalVoid_BMC_HV_13_0:0, SignalVoid_BMC_HV_13_1:0]}, provided-interface=SG_BMC_HV_21
      Vishnu_Test_100Bytes_PDU_NewSignal1_37542d23452fe910: nonqueued-sender-com-spec=Vishnu_Test_100Bytes_PDU_NewSignal1_37542d23452fe910, provided-interface=Vishnu_Test_100Bytes_PDU_NewSignal1_37542d23452fe910
      Vishnu_Test_100Bytes_PDU_NewSignal2_302017e93d94206c: nonqueued-sender-com-spec=Vishnu_Test_100Bytes_PDU_NewSignal2_302017e93d94206c, provided-interface=Vishnu_Test_100Bytes_PDU_NewSignal2_302017e93d94206c
      Vishnu_Test_100Bytes_PDU_NewSignal3_ebd34b418955d5b1: nonqueued-sender-com-spec=Vishnu_Test_100Bytes_PDU_NewSignal3_ebd34b418955d5b1, provided-interface=Vishnu_Test_100Bytes_PDU_NewSignal3_ebd34b418955d5b1
      Vishnu_Test_100Bytes_PDU_NewSignal4_21c239f862026de9: nonqueued-sender-com-spec=Vishnu_Test_100Bytes_PDU_NewSignal4_21c239f862026de9, provided-interface=Vishnu_Test_100Bytes_PDU_NewSignal4_21c239f862026de9
      Vishnu_Test_100Bytes_PDU_NewSignal5_2a9e79b5a4a81ebd: nonqueued-sender-com-spec=Vishnu_Test_100Bytes_PDU_NewSignal5_2a9e79b5a4a81ebd, provided-interface=Vishnu_Test_100Bytes_PDU_NewSignal5_2a9e79b5a4a81ebd
    require port DTC_Test_PDU_Set_Signal_e68158b3301efab7: nonqueued-receiver-com-spec=data-element=DTC_Test_PDU_Set_Signal_e68158b3301efab7, required-interface=DTC_Test_PDU_Set_Signal_e68158b3301efab7
    28 x component:
      ComM: type=ComM
      DemMaster_0: type=DemMaster_0
      DemSatellite_0: type=DemSatellite_0
      Det: type=Det
      SecOC: type=SecOC
      Csm: type=Csm
      EcuM: type=EcuM
      NvM: type=NvM
      Dcm: type=Dcm
      StartApplication: type=StartApplication
      ServiceControl: type=ServiceControl
      Os_OsCore0_swc: type=Os_OsCore0_swc
      Os_OsCore1_swc: type=Os_OsCore1_swc
      WdgM_OsApplication_SystemApplication_Core0: type=WdgM_OsApplication_SystemApplication_Core0
      WdgM_OsApplication_SystemApplication_Core1: type=WdgM_OsApplication_SystemApplication_Core1
      BswM_OsApplication_SystemApplication_Core1: type=BswM_OsApplication_SystemApplication_Core1
      BswM_OsApplication_SystemApplication_Core0: type=BswM_OsApplication_SystemApplication_Core0
      StartApplicationSlaveCore1: type=StartApplicationSlaveCore
      RT_VehComm: type=RT_VehComm
      ShA: type=ShA
      NvA: type=NvA
      DiagA: type=DiagA
      AppDataA: type=AppDataA
      CddNpmGen2: type=CddNpmGen2
      BAPConfig: type=BAPConfig
      ctASG_LSG1: type=ctASG_LSG1
      BAP: type=BAP
      RT_Vishnu: type=RT_Vishnu
    connect DemSatellite_0.Event_DEM_EVENT_StartApplication -> StartApplication.PpDiagnosticMonitor_DEM_EVENT_StartApplication
    connect StartApplication.PpDcmDataService_DID_StartApplication -> Dcm.DataServices_Data_DID_StartApplication
    connect DemMaster_0.OpCycle_PowerCycle -> StartApplication.PpDemOpCycle_PowerCycle
    connect Csm.StartApplication_CsmKey -> StartApplication.PpCsmKeyManagement_StartApplication_CsmKey
    connect StartApplication.PpNvM_RpNotifyJobEnd_StartApplication_NvMBlock1 -> NvM.NvM_RpNotifyJobEnd_StartApplication_NvMBlock1
    connect NvM.PS_StartApplication_NvMBlock1 -> StartApplication.PpPS_StartApplication_NvMBlock1
    connect StartApplication.PpDemDataService_DemDataElementClass_StartApplication -> DemMaster_0.CBReadData_DemDataElementClass_StartApplication
    connect Csm.StartApplication_ECB_AES_Encrypt_Encrypt -> StartApplication.PpStartApplication_ECB_AES_Encrypt
    connect Csm.StartApplication_CsmKey_Dec -> StartApplication.PpStartApplication_CsmKey_Dec
    connect Csm.StartApplication_MAC_Generate_MacGenerate -> StartApplication.PpStartApplication_MAC_Generate
    connect Csm.StartApplication_MAC_Verify_MacVerify -> StartApplication.PpStartApplication_MAC_Verify
    connect Csm.StartApplication_CsmKey_Enc -> StartApplication.PpStartApplication_CsmKey_Enc
    connect Csm.StartApplication_CsmKey_MAC -> StartApplication.PpStartApplication_CsmKey_MAC
    connect Csm.StartApplication_ECB_AES_Decrypt_Decrypt -> StartApplication.PpStartApplication_ECB_AES_Decrypt
    connect NvM.PS_StartApplication_NvMBlock2 -> StartApplication.PpPS_StartApplication_NvMBlock2
    connect StartApplication.PpNvM_RpNotifyJobEnd_StartApplication_NvMBlock2 -> NvM.NvM_RpNotifyJobEnd_StartApplication_NvMBlock2
    connect BswM_OsApplication_SystemApplication_Core0.Switch_ESH_ModeSwitch -> BswM_OsApplication_SystemApplication_Core0.Notification_ESH_ModeNotification
    connect WdgM_OsApplication_SystemApplication_Core0.alive_WdgMSupervisedEntity_StartApplication -> StartApplication.PpAliveWdgMSupervisedEntity_StartApplication
    connect StartApplication.PpMasterCoreData1 -> StartApplicationSlaveCore1.PpMasterCoreData
    connect StartApplicationSlaveCore1.PpSlaveCoreData -> StartApplication.PpSlaveCoreData1
    connect ComM.CW_CN_BMC_CAN01_78a85e89 -> RT_VehComm.CW_CN_BMC_CAN01_78a85e89
    connect ComM.CL_CN_HCP5_CANFD01_54d90215 -> RT_VehComm.CL_CN_HCP5_CANFD01_54d90215
    connect ComM.UR_CN_BMC_CAN01_908d0059 -> RT_VehComm.UR_CN_BMC_CAN01_908d0059
    delegate RT_VehComm.RP_BJB_CALID_Index_01 <-> outer port RP_IF_BJB_CALID_Index_01_XIX_BMC_HV
    connect ComM.UR_CN_HCP5_CANFD01_84d44928 -> RT_VehComm.UR_CN_HCP5_CANFD01_84d44928
    delegate RT_VehComm.R_WFS_VIN_1 <-> outer port RP_IF_VIN_1_XIX_BMC_HV
    delegate RT_VehComm.IF_BMC_EnergieVorhalt <-> outer port SP_IF_BMC_EnergieVorhalt_XIX_BMC_HV
    delegate RT_VehComm.IF_BMC_CMC_Zellspannung_079 <-> outer port SP_IF_BMC_CMC_Zellspannung_079_XIX_BMC_HV
    delegate RT_VehComm.IF_VDSO_Vx3d <-> outer port RP_IF_VDSO_Vx3d_XIX_BMC_HV
    connect ShA.RequestPOSTRUN -> RT_VehComm.RequestPOSTRUN  # UB:Derived from original system description
    connect EcuM.currentMode -> ShA.EcuM_CurrentMode
    connect DiagA.Data_0x0250_Integrity_validation_data_configuration_list -> Dcm.DataServices_Data_DiagnServi_TABROW_IntegValidDataConfiList_Read
    connect DiagA.Routine_0x0253_Calculate_integrity_validation_data_Start -> Dcm.RoutineServices_Routine_DiagnServi_TABROW_CalcuIntegValidData_Start_Routine
    connect DiagA.Routine_0x0254_Calculate_individual_hash_value_Start -> Dcm.RoutineServices_Routine_DiagnServi_TABROW_CalcuIndivHashValue_Start_Routine
    connect DiagA.Data_0x0249_Programming_Hash -> Dcm.DataServices_Data_TABROW_ProgrHash_Read
    connect DiagA.Data_0x0245_Configuration_Hash -> Dcm.DataServices_Data_TABROW_ConfiHash_Read
    connect RT_VehComm.AdaptionCodingOrDsdl2 -> AppDataA.AdaptionCodingOrDsdl2  # UB:Derived from original system description
    connect RT_VehComm.SP_BasicSFD -> Dcm.Dcm_Read_BasicSFDRole
    connect RT_VehComm.SP_E2eSFD -> Dcm.Dcm_Read_E2eSFDRole
    connect RT_VehComm.SP_EptiSFD -> Dcm.Dcm_Read_EptiSFDRole
    connect RT_VehComm.SP_ExtendedSFD -> Dcm.Dcm_Read_ExtendedSFDRole
    connect RT_VehComm.SP_OtaSFD -> Dcm.Dcm_Read_OtaSFDRole
    connect RT_VehComm.SP_ProductionSFD -> Dcm.Dcm_Read_ProductionSFDRole
    connect RT_VehComm.SP_SuperUserSFD -> Dcm.Dcm_Read_SuperUserSFDRole
    connect CddNpmGen2.VetoState -> RT_VehComm.RP_CddNpmGen2_VetoState
    connect CddNpmGen2.BEM3State -> RT_VehComm.RP_CddNpmGen2_BEM3State
    connect RT_VehComm.PP_BswM_MDGP_ESH_RunRequest -> BswM_OsApplication_SystemApplication_Core0.Request_ESH_RunRequest_0
    connect RT_VehComm.DataServices_Data_TABROW_SFDDevelModeActiv_Read -> Dcm.DataServices_Data_TABROW_SFDDevelModeActiv_Read
    delegate RT_VehComm.RP_BJB_ErrMem_State_1 <-> outer port BJB_ErrMem_State_1  # UB:Derived from original system description
    connect BAP.BapReqASG_TestASG_Property_Ack -> ctASG_LSG1.BapReqASG_TestASG_Property_Ack
    connect ctASG_LSG1.BapInd_TestASG_GetAll -> BAP.BapInd_TestASG_GetAll
    connect ctASG_LSG1.BapInd_TestASG_Property -> BAP.BapInd_TestASG_Property
    connect BAP.BapReqASG_TestASG_FunctionList_Get -> ctASG_LSG1.BapReqASG_TestASG_FunctionList_Get
    connect BAP.BAP_SendDebugInfo_Enable -> BAPConfig.BAP_SendDebugInfo_Enable
    connect ctASG_LSG1.BapInd_TestASG_BAPConfig -> BAP.BapInd_TestASG_BAPConfig
    connect ctASG_LSG1.BapInd_TestASG_FunctionList -> BAP.BapInd_TestASG_FunctionList
    connect BAP.BapReqASG_TestASG_GetAll_GetAll -> ctASG_LSG1.BapReqASG_TestASG_GetAll_GetAll
    connect BAP.BapReqASG_TestASG_Property_SetGet -> ctASG_LSG1.BapReqASG_TestASG_Property_SetGet
    connect ctASG_LSG1.Bap_Enable_TestASG -> BAP.Bap_Enable_TestASG
    connect BAP.BapGet_TestASG -> ctASG_LSG1.BapGet_TestASG
    connect BAP.BapReqASG_TestASG_Heartbeat_Get -> ctASG_LSG1.BapReqASG_TestASG_Heartbeat_Get
    connect BAP.BapReqASG_TestASG_BAPConfig_Get -> ctASG_LSG1.BapReqASG_TestASG_BAPConfig_Get
    connect ctASG_LSG1.BapInd_TestASG_Method -> BAP.BapInd_TestASG_Method
    connect ctASG_LSG1.BapInd_TestASG_Array -> BAP.BapInd_TestASG_Array
    connect BAP.BapReqASG_TestASG_Method_StartResult -> ctASG_LSG1.BapReqASG_TestASG_Method_StartResult
    connect BAP.BapReqASG_TestASG_Method_AbortResult -> ctASG_LSG1.BapReqASG_TestASG_Method_AbortResult
    connect ctASG_LSG1.BapInd_TestASG_Heartbeat -> BAP.BapInd_TestASG_Heartbeat
    connect BAP.BapReqASG_TestASG_Array_Get -> ctASG_LSG1.BapReqASG_TestASG_Array_Get
    connect Dcm.DCMServices -> RT_Vishnu.DCMServices
    connect RT_VehComm.DataServices_Data_DiagnServi_TABROW_ActivDiagnSessi_Read -> Dcm.DataServices_Data_DiagnServi_TABROW_ActivDiagnSessi_Read
    delegate RT_VehComm.IF_BMC_CMC_Temperatur_001 <-> outer port SP_IF_BMC_CMC_Temperatur_001_XIX_BMC_HV
    connect RT_VehComm.DataServices_Data_DiagnServi_TABROW_VWSparePartNumbe_Read -> Dcm.DataServices_Data_DiagnServi_TABROW_VWSparePartNumbe_Read
    connect ComM.UR_CN_BMC_CAN01_908d0059 -> RT_Vishnu.UR_CN_BMC_CAN01_908d0059
    connect RT_Vishnu.DataServices_Data_TABROW_VWECUHardwNumbe_Read -> Dcm.DataServices_Data_TABROW_VWECUHardwNumbe_Read
    connect RT_Vishnu.DataServices_Data_DiagnServi_TABROW_VWAppliSoftwVersiNumbe_Read -> Dcm.DataServices_Data_DiagnServi_TABROW_VWAppliSoftwVersiNumbe_Read
    connect DemSatellite_0.Event_DTC_0x10000a -> RT_Vishnu.Event_DTC_0x10000a
    connect DemSatellite_0.Event_DTC_0x10000b -> RT_Vishnu.Event_DTC_0x10000b
    connect DemSatellite_0.Event_DTC_0x10000d -> RT_Vishnu.Event_DTC_0x10000d
    connect Dcm.DcmEcuReset -> RT_Vishnu.DcmEcuReset
    connect RT_Vishnu.ECU_PerformReset -> BswM_OsApplication_SystemApplication_Core0.Notification_SwcModeNotification_IF_ECU_Perform_Reset_Indication
    connect RT_Vishnu.DataServices_Data_HV_Battery_thermal_load_Read_Data_By_Identifier -> Dcm.DataServices_Data_HV_Battery_thermal_load_Read_Data_By_Identifier
    connect DemSatellite_0.Event_DTC_0xe40000 -> RT_Vishnu.Event_DTC_0xe40000
    connect RT_Vishnu.CBReadData_Data_Vishnu_ExtData_Param_VishnRes -> DemMaster_0.CBReadData_Data_Vishnu_ExtData_Param_VishnRes
    connect RT_Vishnu.CBReadData_Data_Vishnu_ExtData_Param_VishnDOB -> DemMaster_0.CBReadData_Data_Vishnu_ExtData_Param_VishnDOB
    connect RT_Vishnu.CBReadData_Data_StandardDTCInformation_Param_DTCPrior -> DemMaster_0.CBReadData_Data_StandardDTCInformation_Param_DTCPrior
    connect RT_Vishnu.CBReadData_Data_SupplementalMonitorActivityData_Param_StoreMonitActivRatio -> DemMaster_0.CBReadData_Data_SupplementalMonitorActivityData_Param_StoreMonitActivRatio
    connect RT_Vishnu.CBReadData_Data_SupplementalMonitorActivityData_Param_MonitActivNumerCount -> DemMaster_0.CBReadData_Data_SupplementalMonitorActivityData_Param_MonitActivNumerCount
    connect RT_Vishnu.CBReadData_Data_StandardFreezeFrame1_Param_TimeStamp_STRUC_Bitfi -> DemMaster_0.CBReadData_Data_StandardFreezeFrame1_Param_TimeStamp_STRUC_Bitfi
    connect RT_Vishnu.CBReadData_Data_StandardFreezeFrame1_Param_Reser -> DemMaster_0.CBReadData_Data_StandardFreezeFrame1_Param_Reser
    connect RT_Vishnu.CBReadData_Data_StandardFreezeFrame1_Param_KmMilea_1 -> DemMaster_0.CBReadData_Data_StandardFreezeFrame1_Param_KmMilea_1
    connect RT_Vishnu.CBReadData_Data_StandardFreezeFrame1_Param_AgingCount -> DemMaster_0.CBReadData_Data_StandardFreezeFrame1_Param_AgingCount
    connect DemSatellite_0.Event_DTC_0xe40013 -> RT_Vishnu.Event_DTC_0xe40013
    connect DemSatellite_0.Event_DTC_0xe40012 -> RT_Vishnu.Event_DTC_0xe40012
    connect DemSatellite_0.Event_DTC_0xe40011 -> RT_Vishnu.Event_DTC_0xe40011
    connect DemMaster_0.ClearDTC_DemClient_DCM -> RT_Vishnu.ClearDTC_DemClient_DCM
    connect RT_Vishnu.CBReadData_DID_0xF40C_Engine_RPM -> DemMaster_0.CBReadData_DID_0xF40C_Engine_RPM
    connect RT_Vishnu.CBReadData_DID_0xF40D_Vehicle_Speed_Sensor -> DemMaster_0.CBReadData_DID_0xF40D_Vehicle_Speed_Sensor
    connect RT_Vishnu.CBReadData_DID_0xF41F_Time_Since_Engin_Start -> DemMaster_0.CBReadData_DID_0xF41F_Time_Since_Engin_Start
    connect RT_Vishnu.CBReadData_DID_0xF404_Calculate_Load_Value -> DemMaster_0.CBReadData_DID_0xF404_Calculate_Load_Value
    connect RT_Vishnu.CBReadData_DID_0xF405_Engine_Coolent_temperature -> DemMaster_0.CBReadData_DID_0xF405_Engine_Coolent_temperature
    connect RT_Vishnu.CBReadData_DID_0xF442_Controle_Module_Voltage -> DemMaster_0.CBReadData_DID_0xF442_Controle_Module_Voltage
    connect RT_Vishnu.CBReadData_DID_0xF449_Accelerator_Pedal_Position_D -> DemMaster_0.CBReadData_DID_0xF449_Accelerator_Pedal_Position_D
    connect RT_Vishnu.DataServices_Data_Vishnu_DID -> Dcm.DataServices_Data_Vishnu_DID
    connect NvM.PS_NvMBlock_0x0250 -> RT_Vishnu.PS_NvMBlock_0x0250
    connect RT_Vishnu.DataServices_Data_Battery_return_flow_temperature_Read_Data_By_Identifier -> Dcm.DataServices_Data_Battery_return_flow_temperature_Read_Data_By_Identifier
    connect RT_Vishnu.SecurityAccess_Unlock_L1 -> Dcm.SecurityAccess_Unlock_L1
    connect CddNpmGen2.K15State -> RT_Vishnu.K15State
    connect NvM.PS_CddNpmGen2_MeasurementsType -> RT_Vishnu.PS_CddNpmGen2_MeasurementsType
    connect DemMaster_0.OpCycle_RT_Test_OpCycle -> RT_Vishnu.OpCycle_RT_Test_OpCycle
    connect RT_Vishnu.DataServices_Data_TABROW_CanTPData_Read -> Dcm.DataServices_Data_TABROW_CanTPData_Read
    connect RT_Vishnu.DataServices_Data_TABROW_PIMDID_Read -> Dcm.DataServices_Data_TABROW_PIMDID_Read
    connect RT_Vishnu.RoutineServices_Routine_DiagnServi_TABROW_NewRoutiBasicSetti_Start_Routine -> Dcm.RoutineServices_Routine_DiagnServi_TABROW_NewRoutiBasicSetti_Start_Routine
    connect DemSatellite_0.Event_DTC_0xd{12000..12002} -> RT_Vishnu.Event_DTC_0xd{12000..12002}
    connect DemSatellite_0.Event_DTC_0xd12004 -> RT_Vishnu.Event_DTC_0xd12004
    connect DemSatellite_0.Event_DTC_0xd12011 -> RT_Vishnu.Event_DTC_0xd12011
    connect DemSatellite_0.Event_DTC_0xd12025 -> RT_Vishnu.Event_DTC_0xd12025
    connect DemSatellite_0.Event_DTC_0xd12026 -> RT_Vishnu.Event_DTC_0xd12026
    connect DemSatellite_0.Event_DTC_0xd{12101..12103} -> RT_Vishnu.Event_DTC_0xd{12101..12103}
    connect DemSatellite_0.Event_DTC_0xe40001 -> RT_Vishnu.Event_DTC_0xe40001
    delegate RT_Vishnu.SG_BMC_HV_17 <-> outer port SG_BMC_HV_17
    connect DemSatellite_0.GeneralEvtInfo -> RT_Vishnu.GeneralEvtInfo
    connect DemMaster_0.ControlDTCSuppression_DemClient_DCM -> RT_Vishnu.ControlDTCSuppression_DemClient_DCM
    delegate RT_Vishnu.SG_BMC_HV_5 <-> outer port SG_BMC_HV_5
    delegate RT_Vishnu.SG_BMC_HV_{19..21} <-> outer port SG_BMC_HV_{19..21}
    delegate RT_Vishnu.SG_BJB_16 <-> outer port SG_BJB_16
    delegate RT_Vishnu.SG_BJB_15 <-> outer port SG_BJB_15
    delegate RT_Vishnu.SG_BJB_13 <-> outer port SG_BJB_13
    delegate RT_Vishnu.SG_BJB_10 <-> outer port SG_BJB_10
    connect RT_Vishnu.SecurityAccess_UnLock_L2 -> Dcm.SecurityAccess_UnLock_L2
    connect RT_Vishnu.DataServices_Data_DiagnServi_TABROW_VWDataSetNumbeOrECUDataContaNumbe_Read -> Dcm.DataServices_Data_DiagnServi_TABROW_VWDataSetNumbeOrECUDataContaNumbe_Read
    delegate RT_Vishnu.DTC_Test_PDU_Set_Signal_e68158b3301efab7 <-> outer port DTC_Test_PDU_Set_Signal_e68158b3301efab7
  end to end protection set E2EPROTECTIONSET
  port interface mapping set PORTINTERFACEMAPPINGSET
